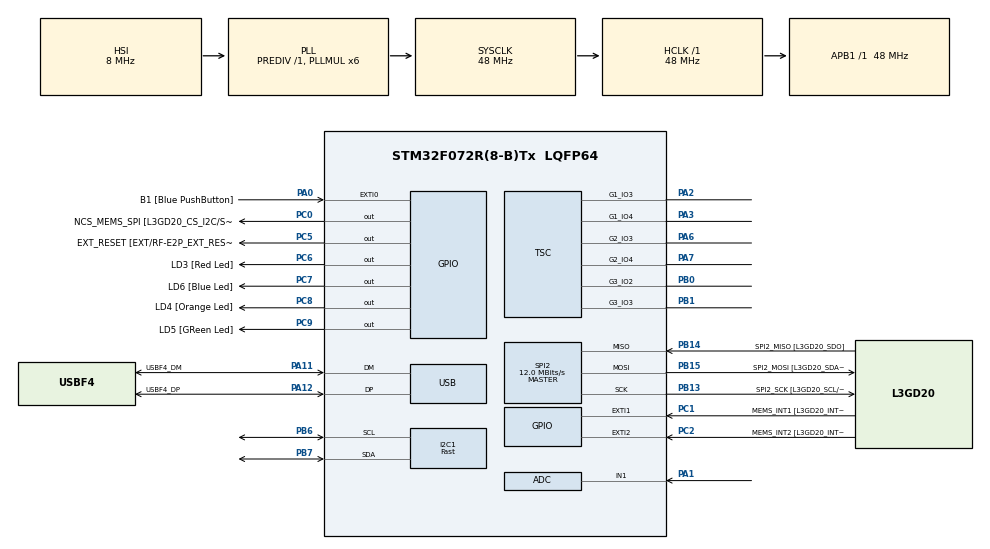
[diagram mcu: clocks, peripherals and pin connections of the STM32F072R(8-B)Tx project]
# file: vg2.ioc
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I2C1.I2C_Speed_Mode=I2C_Fast
I2C1.Timing=0x0010020A
Mcu.Family=STM32F0
Mcu.Name=STM32F072R(8-B)Tx
Mcu.Package=LQFP64
Mcu.UserConstants=dingastest,2137
PA0.GPIO_Label=B1 [Blue PushButton]
PA0.GPIO_ModeDefaultEXTI=GPIO_MODE_EVT_RISING
PA0.Signal=GPXTI0
PA1.Mode=IN1
PA1.Signal=ADC_IN1
PA11.GPIO_Label=USBF4_DM
PA11.Mode=Device
PA11.Signal=USB_DM
PA12.GPIO_Label=USBF4_DP
PA12.Mode=Device
PA12.Signal=USB_DP
PA13.GPIO_Label=SWDIO
PA13.Mode=Serial_Wire
PA13.Signal=SYS_SWDIO
PA14.GPIO_Label=SWCLK
PA14.Mode=Serial_Wire
PA14.Signal=SYS_SWCLK
PA2.Mode=G1_IO3-Channel
PA2.Signal=TSC_G1_IO3
PA3.Mode=G1_IO4-Sampling
PA3.Signal=TSC_G1_IO4
PA6.Mode=G2_IO3-Channel
PA6.Signal=TSC_G2_IO3
PA7.Mode=G2_IO4-Sampling
PA7.Signal=TSC_G2_IO4
PB0.Mode=G3_IO2-Channel
PB0.Signal=TSC_G3_IO2
PB1.Mode=G3_IO3-Sampling
PB1.Signal=TSC_G3_IO3
PB10.GPIO_Label=I2C2_SCL[EXT/RF-E2P_SCL]
PB10.GPIO_Pu=GPIO_PULLUP
PB10.Signal=I2C2_SCL
PB11.GPIO_Label=I2C2_SDA[EXT/RF-E2P_SDA]
PB11.GPIO_Pu=GPIO_PULLUP
PB11.Signal=I2C2_SDA
PB13.GPIO_Label=SPI2_SCK [L3GD20_SCL/SPC]
PB13.Mode=Full_Duplex_Master
PB13.Signal=SPI2_SCK
PB14.GPIO_Label=SPI2_MISO [L3GD20_SDO]
PB14.Mode=Full_Duplex_Master
PB14.Signal=SPI2_MISO
PB15.GPIO_Label=SPI2_MOSI [L3GD20_SDA/SDI]
PB15.Mode=Full_Duplex_Master
PB15.Signal=SPI2_MOSI
PB6.Mode=I2C
PB6.Signal=I2C1_SCL
PB7.Mode=I2C
PB7.Signal=I2C1_SDA
PC0.GPIO_Label=NCS_MEMS_SPI [L3GD20_CS_I2C/SPI]
PC0.Signal=GPIO_Output
PC1.GPIO_Label=MEMS_INT1 [L3GD20_INT1]
PC1.GPIO_ModeDefaultEXTI=GPIO_MODE_EVT_RISING
PC1.Signal=GPXTI1
PC2.GPIO_Label=MEMS_INT2 [L3GD20_INT2]
PC2.GPIO_ModeDefaultEXTI=GPIO_MODE_EVT_RISING
PC2.Signal=GPXTI2
PC5.GPIO_Label=EXT_RESET [EXT/RF-E2P_EXT_RESET]
PC5.Signal=GPIO_Output
PC6.GPIO_Label=LD3 [Red Led]
PC6.Signal=GPIO_Output
PC7.GPIO_Label=LD6 [Blue Led]
PC7.Signal=GPIO_Output
PC8.GPIO_Label=LD4 [Orange Led]
PC8.Signal=GPIO_Output
PC9.GPIO_Label=LD5 [GReen Led]
PC9.Signal=GPIO_Output
ProjectManager.HeapSize=0x200
ProjectManager.StackSize=0x400
ProjectManager.TargetToolchain=STM32CubeIDE
RCC.AHBFreq_Value=48000000
RCC.APB1Freq_Value=48000000
RCC.APB1TimFreq_Value=48000000
RCC.HCLKFreq_Value=48000000
RCC.PLLMUL=RCC_PLL_MUL6
RCC.SYSCLKFreq_VALUE=48000000
RCC.SYSCLKSource=RCC_SYSCLKSOURCE_PLLCLK
SPI2.BaudRatePrescaler=SPI_BAUDRATEPRESCALER_4
SPI2.CalculateBaudRate=12.0 MBits/s
SPI2.Direction=SPI_DIRECTION_2LINES
SPI2.Mode=SPI_MODE_MASTER
SPI2.VirtualType=VM_MASTER
TSC.ChannelIOs-G1_IO3=TSC_GROUP1_IO3
TSC.ChannelIOs-G2_IO3=TSC_GROUP2_IO3
TSC.ChannelIOs-G3_IO2=TSC_GROUP3_IO2
TSC.SamplingIOs-G1_IO4=TSC_GROUP1_IO4
TSC.SamplingIOs-G2_IO4=TSC_GROUP2_IO4
TSC.SamplingIOs-G3_IO3=TSC_GROUP3_IO3
USB.phy_itface=PCD_PHY_EMBEDDED
USB.speed=PCD_SPEED_FULL
board=STM32F072B-DISCO

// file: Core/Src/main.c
/* USER CODE BEGIN Header */
/**
  ******************************************************************************
  * @file           : main.c
  * @brief          : Main program body
  ******************************************************************************
  * @attention
  *
  * Copyright (c) 2025 STMicroelectronics.
  * All rights reserved.
  *
  * This software is licensed under terms that can be found in the LICENSE file
  * in the root directory of this software component.
  * If no LICENSE file comes with this software, it is provided AS-IS.
  *
  ******************************************************************************
  */

/* USER CODE END Header */
#include "main.h"

/* USER CODE BEGIN Includes */
#include "ssd1306.h"
#include "ssd1306_tests.h"
#include "ssd1306_fonts.h"
#include <stdio.h>
/* USER CODE END Includes */

ADC_HandleTypeDef hadc;
DMA_HandleTypeDef hdma_adc;

I2C_HandleTypeDef hi2c1;

SPI_HandleTypeDef hspi2;

TSC_HandleTypeDef htsc;

PCD_HandleTypeDef hpcd_USB_FS;

void SystemClock_Config(void);
static void MX_GPIO_Init(void);
static void MX_DMA_Init(void);
static void MX_SPI2_Init(void);
static void MX_TSC_Init(void);
static void MX_USB_PCD_Init(void);
static void MX_I2C1_Init(void);
static void MX_ADC_Init(void);

/* USER CODE BEGIN 0 */

// CONSTS FOR FACES
const unsigned char image_data_demo_angry[] = {
    0x00, 0x00, 0x00, 0x00, 0x00, 0x00, 0x00, 0x00, 0x00, 0x00, 0x00, 0x00, 0x00, 0x00, 0x00, 0x00,
    0x00, 0x00, 0x00, 0x00, 0x00, 0x00, 0x00, 0x00, 0x00, 0x00, 0x00, 0x00, 0x00, 0x00, 0x00, 0x00,
    0x00, 0x00, 0x00, 0x00, 0x00, 0x00, 0x00, 0x00, 0x00, 0x00, 0x00, 0x00, 0x00, 0x00, 0x00, 0x00,
    0x00, 0x00, 0x00, 0x00, 0x00, 0x00, 0x00, 0x00, 0x00, 0x00, 0x00, 0x00, 0x00, 0x00, 0x00, 0x00,
    0x00, 0x00, 0x00, 0x00, 0x00, 0x00, 0x00, 0x00, 0x00, 0x00, 0x00, 0x00, 0x00, 0x00, 0x00, 0x00,
    0x00, 0x00, 0x00, 0x00, 0x00, 0x00, 0x00, 0x00, 0x00, 0x00, 0x00, 0x00, 0x00, 0x00, 0x00, 0x00,
    0x00, 0x00, 0x00, 0x00, 0x00, 0x00, 0x00, 0x00, 0x00, 0x00, 0x00, 0x00, 0x00, 0x00, 0x00, 0x00,
    0x00, 0x00, 0x00, 0x00, 0x00, 0x00, 0x00, 0x00, 0x00, 0x00, 0x00, 0x00, 0x00, 0x00, 0x00, 0x00,
    0x00, 0x00, 0x00, 0x00, 0x00, 0x00, 0x00, 0x00, 0x00, 0x00, 0x00, 0x00, 0x00, 0x00, 0x00, 0x00,
    0x00, 0x00, 0x00, 0x00, 0x00, 0x00, 0x80, 0x00, 0x00, 0x04, 0x00, 0x00, 0x00, 0x00, 0x00, 0x00,
    0x00, 0x00, 0x00, 0x00, 0x00, 0x01, 0xE0, 0x00, 0x00, 0x0E, 0x00, 0x00, 0x00, 0x00, 0x00, 0x00,
    0x00, 0x00, 0x00, 0x00, 0x00, 0x01, 0xF8, 0x00, 0x00, 0x1E, 0x00, 0x00, 0x00, 0x00, 0x00, 0x00,
    0x00, 0x00, 0x00, 0x00, 0x00, 0x00, 0xFE, 0x00, 0x00, 0x3C, 0x00, 0x00, 0x00, 0x00, 0x00, 0x00,
    0x00, 0x00, 0x00, 0x00, 0x00, 0x00, 0x3F, 0x00, 0x00, 0x78, 0x00, 0x00, 0x00, 0x00, 0x00, 0x00,
    0x00, 0x00, 0x00, 0x00, 0x00, 0x00, 0x1F, 0xC0, 0x00, 0xF0, 0x00, 0x00, 0x00, 0x00, 0x00, 0x00,
    0x00, 0x00, 0x00, 0x00, 0x00, 0x00, 0x07, 0xE0, 0x03, 0xE0, 0x00, 0x00, 0x00, 0x00, 0x00, 0x00,
    0x00, 0x00, 0x00, 0x00, 0x00, 0x00, 0x01, 0xF8, 0x07, 0xC0, 0x00, 0x00, 0x00, 0x00, 0x00, 0x00,
    0x00, 0x00, 0x00, 0x00, 0x00, 0x00, 0x00, 0x7C, 0x0F, 0x00, 0x00, 0x00, 0x00, 0x00, 0x00, 0x00,
    0x00, 0x00, 0x00, 0x00, 0x00, 0x00, 0x00, 0x3E, 0x1E, 0x00, 0x00, 0x00, 0x00, 0x00, 0x00, 0x00,
    0x00, 0x00, 0x00, 0x00, 0x00, 0x01, 0xE0, 0x0F, 0x3C, 0x03, 0xC0, 0x00, 0x00, 0x00, 0x00, 0x00,
    0x00, 0x00, 0x00, 0x00, 0x00, 0x03, 0xF0, 0x06, 0x18, 0x07, 0xE0, 0x00, 0x00, 0x00, 0x00, 0x00,
    0x00, 0x00, 0x00, 0x00, 0x00, 0x07, 0xF8, 0x00, 0x00, 0x0F, 0xF0, 0x00, 0x00, 0x00, 0x00, 0x00,
    0x00, 0x00, 0x00, 0x00, 0x00, 0x0F, 0xFC, 0x00, 0x00, 0x1F, 0xF8, 0x00, 0x00, 0x00, 0x00, 0x00,
    0x00, 0x00, 0x00, 0x00, 0x00, 0x0F, 0xFC, 0x00, 0x00, 0x1F, 0xF8, 0x00, 0x00, 0x00, 0x00, 0x00,
    0x00, 0x00, 0x00, 0x00, 0x00, 0x0F, 0xFC, 0x00, 0x00, 0x1F, 0xF8, 0x00, 0x00, 0x00, 0x00, 0x00,
    0x00, 0x00, 0x00, 0x00, 0x00, 0x0F, 0xFC, 0x00, 0x00, 0x1F, 0xF8, 0x00, 0x00, 0x00, 0x00, 0x00,
    0x00, 0x00, 0x00, 0x00, 0x00, 0x07, 0xF8, 0x00, 0x00, 0x0F, 0xF0, 0x00, 0x00, 0x00, 0x00, 0x00,
    0x00, 0x00, 0x00, 0x00, 0x00, 0x03, 0xF0, 0x00, 0x00, 0x07, 0xE0, 0x00, 0x00, 0x00, 0x00, 0x00,
    0x00, 0x00, 0x00, 0x00, 0x00, 0x01, 0xE0, 0x00, 0x00, 0x03, 0xC0, 0x00, 0x00, 0x00, 0x00, 0x00,
    0x00, 0x00, 0x00, 0x00, 0x00, 0x00, 0x00, 0x00, 0x00, 0x00, 0x00, 0x00, 0x00, 0x00, 0x00, 0x00,
    0x00, 0x00, 0x00, 0x00, 0x00, 0x00, 0x00, 0x00, 0x00, 0x00, 0x00, 0x00, 0x00, 0x00, 0x00, 0x00,
    0x00, 0x00, 0x00, 0x00, 0x00, 0x00, 0x00, 0x00, 0x00, 0x00, 0x00, 0x00, 0x00, 0x00, 0x00, 0x00,
    0x00, 0x00, 0x00, 0x00, 0x00, 0x00, 0x00, 0x03, 0x80, 0x00, 0x00, 0x00, 0x00, 0x00, 0x00, 0x00,
    0x00, 0x00, 0x00, 0x00, 0x00, 0x00, 0x00, 0x07, 0xC0, 0x00, 0x00, 0x00, 0x00, 0x00, 0x00, 0x00,
    0x00, 0x00, 0x00, 0x00, 0x00, 0x00, 0x00, 0x07, 0xE0, 0x00, 0x00, 0x00, 0x00, 0x00, 0x00, 0x00,
    0x00, 0x00, 0x00, 0x00, 0x00, 0x00, 0x00, 0x0E, 0xF0, 0x00, 0x00, 0x00, 0x00, 0x00, 0x00, 0x00,
    0x00, 0x00, 0x00, 0x00, 0x00, 0x00, 0x00, 0x1E, 0x78, 0x00, 0x00, 0x00, 0x00, 0x00, 0x00, 0x00,
    0x00, 0x00, 0x00, 0x00, 0x00, 0x00, 0x00, 0x3C, 0x3C, 0x00, 0x00, 0x00, 0x00, 0x00, 0x00, 0x00,
    0x00, 0x00, 0x00, 0x00, 0x00, 0x00, 0x00, 0x78, 0x1E, 0x00, 0x00, 0x00, 0x00, 0x00, 0x00, 0x00,
    0x00, 0x00, 0x00, 0x00, 0x00, 0x00, 0x00, 0x70, 0x0F, 0x00, 0x00, 0x00, 0x00, 0x00, 0x00, 0x00,
    0x00, 0x00, 0x00, 0x00, 0x00, 0x00, 0x00, 0xF0, 0x03, 0x80, 0x00, 0x00, 0x00, 0x00, 0x00, 0x00,
    0x00, 0x00, 0x00, 0x00, 0x00, 0x00, 0x00, 0xE0, 0x03, 0xC0, 0x00, 0x00, 0x00, 0x00, 0x00, 0x00,
    0x00, 0x00, 0x00, 0x00, 0x00, 0x00, 0x00, 0x40, 0x01, 0x80, 0x00, 0x00, 0x00, 0x00, 0x00, 0x00,
    0x00, 0x00, 0x00, 0x00, 0x00, 0x00, 0x00, 0x00, 0x00, 0x00, 0x00, 0x00, 0x00, 0x00, 0x00, 0x00,
    0x00, 0x00, 0x00, 0x00, 0x00, 0x00, 0x00, 0x00, 0x00, 0x00, 0x00, 0x00, 0x00, 0x00, 0x00, 0x00,
    0x00, 0x00, 0x00, 0x00, 0x00, 0x00, 0x00, 0x00, 0x00, 0x00, 0x00, 0x00, 0x00, 0x00, 0x00, 0x00,
    0x00, 0x00, 0x00, 0x00, 0x00, 0x00, 0x00, 0x00, 0x00, 0x00, 0x00, 0x00, 0x00, 0x00, 0x00, 0x00,
    0x00, 0x00, 0x00, 0x00, 0x00, 0x00, 0x00, 0x00, 0x00, 0x00, 0x00, 0x00, 0x00, 0x00, 0x00, 0x00,
    0x00, 0x00, 0x00, 0x00, 0x00, 0x00, 0x00, 0x00, 0x00, 0x00, 0x00, 0x00, 0x00, 0x00, 0x00, 0x00,
    0x00, 0x00, 0x00, 0x00, 0x00, 0x00, 0x00, 0x00, 0x00, 0x00, 0x00, 0x00, 0x00, 0x00, 0x00, 0x00,
    0x00, 0x00, 0x00, 0x00, 0x00, 0x00, 0x00, 0x00, 0x00, 0x00, 0x00, 0x00, 0x00, 0x00, 0x00, 0x00,
    0x00, 0x00, 0x00, 0x00, 0x00, 0x00, 0x00, 0x00, 0x00, 0x00, 0x00, 0x00, 0x00, 0x00, 0x00, 0x00,
    0x00, 0x00, 0x00, 0x00, 0x00, 0x00, 0x00, 0x00, 0x00, 0x00, 0x00, 0x00, 0x00, 0x00, 0x00, 0x00,
    0x00, 0x00, 0x00, 0x00, 0x00, 0x00, 0x00, 0x00, 0x00, 0x00, 0x00, 0x00, 0x00, 0x00, 0x00, 0x00,
    0x00, 0x00, 0x00, 0x00, 0x00, 0x00, 0x00, 0x00, 0x00, 0x00, 0x00, 0x00, 0x00, 0x00, 0x00, 0x00,
    0x00, 0x00, 0x00, 0x00, 0x00, 0x00, 0x00, 0x00, 0x00, 0x00, 0x00, 0x00, 0x00, 0x00, 0x00, 0x00,
    0x00, 0x00, 0x00, 0x00, 0x00, 0x00, 0x00, 0x00, 0x00, 0x00, 0x00, 0x00, 0x00, 0x00, 0x00, 0x00,
    0x00, 0x00, 0x00, 0x00, 0x00, 0x00, 0x00, 0x00, 0x00, 0x00, 0x00, 0x00, 0x00, 0x00, 0x00, 0x00,
    0x00, 0x00, 0x00, 0x00, 0x00, 0x00, 0x00, 0x00, 0x00, 0x00, 0x00, 0x00, 0x00, 0x00, 0x00, 0x00,
    0x00, 0x00, 0x00, 0x00, 0x00, 0x00, 0x00, 0x00, 0x00, 0x00, 0x00, 0x00, 0x00, 0x00, 0x00, 0x00,
    0x00, 0x00, 0x00, 0x00, 0x00, 0x00, 0x00, 0x00, 0x00, 0x00, 0x00, 0x00, 0x00, 0x00, 0x00, 0x00,
    0x00, 0x00, 0x00, 0x00, 0x00, 0x00, 0x00, 0x00, 0x00, 0x00, 0x00, 0x00, 0x00, 0x00, 0x00, 0x00,
    0x00, 0x00, 0x00, 0x00, 0x00, 0x00, 0x00, 0x00, 0x00, 0x00, 0x00, 0x00, 0x00, 0x00, 0x00, 0x00,
    0x00, 0x00, 0x00, 0x00, 0x00, 0x00, 0x00, 0x00, 0x00, 0x00, 0x00, 0x00, 0x00, 0x00, 0x00, 0x00
};

const unsigned char image_data_demo_smiley[] = {
    0x00, 0x00, 0x00, 0x00, 0x00, 0x00, 0x00, 0x00, 0x00, 0x00, 0x00, 0x00, 0x00, 0x00, 0x00, 0x00,
    0x00, 0x00, 0x00, 0x00, 0x00, 0x00, 0x00, 0x00, 0x00, 0x00, 0x00, 0x00, 0x00, 0x00, 0x00, 0x00,
    0x00, 0x00, 0x00, 0x00, 0x00, 0x00, 0x00, 0x00, 0x00, 0x00, 0x00, 0x00, 0x00, 0x00, 0x00, 0x00,
    0x00, 0x00, 0x00, 0x00, 0x00, 0x00, 0x00, 0x00, 0x00, 0x00, 0x00, 0x00, 0x00, 0x00, 0x00, 0x00,
    0x00, 0x00, 0x00, 0x00, 0x00, 0x00, 0x00, 0x00, 0x00, 0x00, 0x00, 0x00, 0x00, 0x00, 0x00, 0x00,
    0x00, 0x00, 0x00, 0x00, 0x00, 0x00, 0x00, 0x00, 0x00, 0x00, 0x00, 0x00, 0x00, 0x00, 0x00, 0x00,
    0x00, 0x00, 0x00, 0x00, 0x00, 0x00, 0x00, 0x00, 0x00, 0x00, 0x00, 0x00, 0x00, 0x00, 0x00, 0x00,
    0x00, 0x00, 0x00, 0x00, 0x00, 0x00, 0x00, 0x00, 0x00, 0x00, 0x00, 0x00, 0x00, 0x00, 0x00, 0x00,
    0x00, 0x00, 0x00, 0x00, 0x00, 0x00, 0x00, 0x00, 0x00, 0x00, 0x00, 0x00, 0x00, 0x00, 0x00, 0x00,
    0x00, 0x00, 0x00, 0x00, 0x00, 0x00, 0x00, 0x00, 0x00, 0x00, 0x00, 0x00, 0x00, 0x00, 0x00, 0x00,
    0x00, 0x00, 0x00, 0x00, 0x00, 0x00, 0x00, 0x00, 0x00, 0x00, 0x00, 0x00, 0x00, 0x00, 0x00, 0x00,
    0x00, 0x00, 0x00, 0x00, 0x00, 0x00, 0x00, 0x00, 0x00, 0x00, 0x00, 0x00, 0x00, 0x00, 0x00, 0x00,
    0x00, 0x00, 0x00, 0x00, 0x00, 0x00, 0x00, 0x00, 0x00, 0x00, 0x00, 0x00, 0x00, 0x00, 0x00, 0x00,
    0x00, 0x00, 0x00, 0x00, 0x00, 0x00, 0x00, 0x00, 0x00, 0x00, 0x00, 0x00, 0x00, 0x00, 0x00, 0x00,
    0x00, 0x00, 0x00, 0x00, 0x00, 0x00, 0x00, 0x00, 0x00, 0x00, 0x00, 0x00, 0x00, 0x00, 0x00, 0x00,
    0x00, 0x00, 0x00, 0x00, 0x00, 0x00, 0x00, 0x00, 0x00, 0x00, 0x00, 0x00, 0x00, 0x00, 0x00, 0x00,
    0x00, 0x00, 0x00, 0x00, 0x00, 0x00, 0x00, 0x00, 0x00, 0x00, 0x00, 0x00, 0x00, 0x00, 0x00, 0x00,
    0x00, 0x00, 0x00, 0x00, 0x00, 0x00, 0x00, 0x00, 0x00, 0x00, 0x00, 0x00, 0x00, 0x00, 0x00, 0x00,
    0x00, 0x00, 0x00, 0x00, 0x00, 0x00, 0x00, 0x00, 0x00, 0x00, 0x00, 0x00, 0x00, 0x00, 0x00, 0x00,
    0x00, 0x00, 0x00, 0x00, 0x00, 0x01, 0xE0, 0x00, 0x00, 0x03, 0xC0, 0x00, 0x00, 0x00, 0x00, 0x00,
    0x00, 0x00, 0x00, 0x00, 0x00, 0x03, 0xF0, 0x00, 0x00, 0x07, 0xE0, 0x00, 0x00, 0x00, 0x00, 0x00,
    0x00, 0x00, 0x00, 0x00, 0x00, 0x07, 0xF8, 0x00, 0x00, 0x0F, 0xF0, 0x00, 0x00, 0x00, 0x00, 0x00,
    0x00, 0x00, 0x00, 0x00, 0x00, 0x0F, 0xFC, 0x00, 0x00, 0x1F, 0xF8, 0x00, 0x00, 0x00, 0x00, 0x00,
    0x00, 0x00, 0x00, 0x00, 0x00, 0x0F, 0xFC, 0x00, 0x00, 0x1F, 0xF8, 0x00, 0x00, 0x00, 0x00, 0x00,
    0x00, 0x00, 0x00, 0x00, 0x00, 0x0F, 0xFC, 0x00, 0x00, 0x1F, 0xF8, 0x00, 0x00, 0x00, 0x00, 0x00,
    0x00, 0x00, 0x00, 0x00, 0x00, 0x0F, 0xFC, 0x00, 0x00, 0x1F, 0xF8, 0x00, 0x00, 0x00, 0x00, 0x00,
    0x00, 0x00, 0x00, 0x00, 0x00, 0x07, 0xF8, 0x00, 0x00, 0x0F, 0xF0, 0x00, 0x00, 0x00, 0x00, 0x00,
    0x00, 0x00, 0x00, 0x00, 0x00, 0x03, 0xF0, 0x00, 0x00, 0x07, 0xE0, 0x00, 0x00, 0x00, 0x00, 0x00,
    0x00, 0x00, 0x00, 0x00, 0x00, 0x01, 0xE0, 0x00, 0x00, 0x03, 0xC0, 0x00, 0x00, 0x00, 0x00, 0x00,
    0x00, 0x00, 0x00, 0x00, 0x00, 0x00, 0x00, 0x00, 0x00, 0x00, 0x00, 0x00, 0x00, 0x00, 0x00, 0x00,
    0x00, 0x00, 0x00, 0x00, 0x00, 0x00, 0x00, 0x00, 0x00, 0x00, 0x00, 0x00, 0x00, 0x00, 0x00, 0x00,
    0x00, 0x00, 0x00, 0x00, 0x00, 0x00, 0x00, 0x00, 0x00, 0x00, 0x00, 0x00, 0x00, 0x00, 0x00, 0x00,
    0x00, 0x00, 0x00, 0x00, 0x00, 0x00, 0x00, 0x00, 0x00, 0x00, 0x00, 0x00, 0x00, 0x00, 0x00, 0x00,
    0x00, 0x00, 0x00, 0x00, 0x00, 0x00, 0x00, 0x00, 0x00, 0x00, 0x00, 0x00, 0x00, 0x00, 0x00, 0x00,
    0x00, 0x00, 0x00, 0x00, 0x00, 0x00, 0x00, 0x00, 0x00, 0x00, 0x00, 0x00, 0x00, 0x00, 0x00, 0x00,
    0x00, 0x00, 0x00, 0x00, 0x00, 0x00, 0x00, 0x01, 0x00, 0x00, 0x00, 0x00, 0x00, 0x00, 0x00, 0x00,
    0x00, 0x00, 0x00, 0x00, 0x00, 0x00, 0x04, 0x03, 0x80, 0x60, 0x00, 0x00, 0x00, 0x00, 0x00, 0x00,
    0x00, 0x00, 0x00, 0x00, 0x00, 0x00, 0x0E, 0x03, 0xC0, 0xF0, 0x00, 0x00, 0x00, 0x00, 0x00, 0x00,
    0x00, 0x00, 0x00, 0x00, 0x00, 0x00, 0x0F, 0x87, 0xE1, 0xE0, 0x00, 0x00, 0x00, 0x00, 0x00, 0x00,
    0x00, 0x00, 0x00, 0x00, 0x00, 0x00, 0x07, 0xFF, 0xFF, 0xC0, 0x00, 0x00, 0x00, 0x00, 0x00, 0x00,
    0x00, 0x00, 0x00, 0x00, 0x00, 0x00, 0x03, 0xFE, 0x7F, 0x80, 0x00, 0x00, 0x00, 0x00, 0x00, 0x00,
    0x00, 0x00, 0x00, 0x00, 0x00, 0x00, 0x00, 0xFC, 0x3F, 0x00, 0x00, 0x00, 0x00, 0x00, 0x00, 0x00,
    0x00, 0x00, 0x00, 0x00, 0x00, 0x00, 0x00, 0x00, 0x00, 0x00, 0x00, 0x00, 0x00, 0x00, 0x00, 0x00,
    0x00, 0x00, 0x00, 0x00, 0x00, 0x00, 0x00, 0x00, 0x00, 0x00, 0x00, 0x00, 0x00, 0x00, 0x00, 0x00,
    0x00, 0x00, 0x00, 0x00, 0x00, 0x00, 0x00, 0x00, 0x00, 0x00, 0x00, 0x00, 0x00, 0x00, 0x00, 0x00,
    0x00, 0x00, 0x00, 0x00, 0x00, 0x00, 0x00, 0x00, 0x00, 0x00, 0x00, 0x00, 0x00, 0x00, 0x00, 0x00,
    0x00, 0x00, 0x00, 0x00, 0x00, 0x00, 0x00, 0x00, 0x00, 0x00, 0x00, 0x00, 0x00, 0x00, 0x00, 0x00,
    0x00, 0x00, 0x00, 0x00, 0x00, 0x00, 0x00, 0x00, 0x00, 0x00, 0x00, 0x00, 0x00, 0x00, 0x00, 0x00,
    0x00, 0x00, 0x00, 0x00, 0x00, 0x00, 0x00, 0x00, 0x00, 0x00, 0x00, 0x00, 0x00, 0x00, 0x00, 0x00,
    0x00, 0x00, 0x00, 0x00, 0x00, 0x00, 0x00, 0x00, 0x00, 0x00, 0x00, 0x00, 0x00, 0x00, 0x00, 0x00,
    0x00, 0x00, 0x00, 0x00, 0x00, 0x00, 0x00, 0x00, 0x00, 0x00, 0x00, 0x00, 0x00, 0x00, 0x00, 0x00,
    0x00, 0x00, 0x00, 0x00, 0x00, 0x00, 0x00, 0x00, 0x00, 0x00, 0x00, 0x00, 0x00, 0x00, 0x00, 0x00,
    0x00, 0x00, 0x00, 0x00, 0x00, 0x00, 0x00, 0x00, 0x00, 0x00, 0x00, 0x00, 0x00, 0x00, 0x00, 0x00,
    0x00, 0x00, 0x00, 0x00, 0x00, 0x00, 0x00, 0x00, 0x00, 0x00, 0x00, 0x00, 0x00, 0x00, 0x00, 0x00,
    0x00, 0x00, 0x00, 0x00, 0x00, 0x00, 0x00, 0x00, 0x00, 0x00, 0x00, 0x00, 0x00, 0x00, 0x00, 0x00,
    0x00, 0x00, 0x00, 0x00, 0x00, 0x00, 0x00, 0x00, 0x00, 0x00, 0x00, 0x00, 0x00, 0x00, 0x00, 0x00,
    0x00, 0x00, 0x00, 0x00, 0x00, 0x00, 0x00, 0x00, 0x00, 0x00, 0x00, 0x00, 0x00, 0x00, 0x00, 0x00,
    0x00, 0x00, 0x00, 0x00, 0x00, 0x00, 0x00, 0x00, 0x00, 0x00, 0x00, 0x00, 0x00, 0x00, 0x00, 0x00,
    0x00, 0x00, 0x00, 0x00, 0x00, 0x00, 0x00, 0x00, 0x00, 0x00, 0x00, 0x00, 0x00, 0x00, 0x00, 0x00,
    0x00, 0x00, 0x00, 0x00, 0x00, 0x00, 0x00, 0x00, 0x00, 0x00, 0x00, 0x00, 0x00, 0x00, 0x00, 0x00,
    0x00, 0x00, 0x00, 0x00, 0x00, 0x00, 0x00, 0x00, 0x00, 0x00, 0x00, 0x00, 0x00, 0x00, 0x00, 0x00,
    0x00, 0x00, 0x00, 0x00, 0x00, 0x00, 0x00, 0x00, 0x00, 0x00, 0x00, 0x00, 0x00, 0x00, 0x00, 0x00,
    0x00, 0x00, 0x00, 0x00, 0x00, 0x00, 0x00, 0x00, 0x00, 0x00, 0x00, 0x00, 0x00, 0x00, 0x00, 0x00,
    0x00, 0x00, 0x00, 0x00, 0x00, 0x00, 0x00, 0x00, 0x00, 0x00, 0x00, 0x00, 0x00, 0x00, 0x00, 0x00
};

const unsigned char image_data_cry_1[] = {
    0xFF, 0xFF, 0xFF, 0xFF, 0xFF, 0xFF, 0xFF, 0xFF, 0xFF, 0xFF, 0xFF, 0xFF, 0xFF, 0xFF, 0xFF, 0xFF,
    0xFF, 0xFF, 0xFF, 0xFF, 0xFF, 0xFF, 0xFF, 0xFF, 0xFF, 0xFF, 0xFF, 0xFF, 0xFF, 0xFF, 0xFF, 0xFF,
    0xFF, 0xFF, 0xFF, 0xFF, 0xFF, 0xFF, 0xFF, 0xFF, 0xFF, 0xFF, 0xFF, 0xFF, 0xFF, 0xFF, 0xFF, 0xFF,
    0xFF, 0xFF, 0xFF, 0xFF, 0xFF, 0xFF, 0xFF, 0xFF, 0xFF, 0xFF, 0xFF, 0xFF, 0xFF, 0xFF, 0xFF, 0xFF,
    0xFF, 0xFF, 0xFF, 0xFF, 0xFF, 0xFF, 0xFF, 0xFF, 0xFF, 0xFF, 0xFF, 0xFF, 0xFF, 0xFF, 0xFF, 0xFF,
    0xFF, 0xFF, 0xFF, 0xFF, 0xFF, 0xFF, 0xFF, 0xFF, 0xFF, 0xFF, 0xFF, 0xFF, 0xFF, 0xFF, 0xFF, 0xFF,
    0xFF, 0xFF, 0xFF, 0xFF, 0xFF, 0xFF, 0xFF, 0xFF, 0xFF, 0xFF, 0xFF, 0xFF, 0xFF, 0xFF, 0xFF, 0xFF,
    0xFF, 0xFF, 0xFF, 0xFF, 0xFF, 0xFF, 0xFF, 0xFF, 0xFF, 0xFF, 0xFF, 0xFF, 0xFF, 0xFF, 0xFF, 0xFF,
    0xFF, 0xFF, 0xFF, 0xFF, 0xFF, 0xE7, 0xFF, 0xFF, 0xFF, 0xDF, 0xFF, 0xFF, 0xFF, 0xFF, 0xFF, 0xFF,
    0xFF, 0xFF, 0xFF, 0xFF, 0xFF, 0xCB, 0xFF, 0xFF, 0xFF, 0x87, 0xFF, 0xFF, 0xFF, 0xFF, 0xFF, 0xFF,
    0xFF, 0xFF, 0xFF, 0xFF, 0xFF, 0x9D, 0xFF, 0xFF, 0xFF, 0x33, 0xFF, 0xFF, 0xFF, 0xFF, 0xFF, 0xFF,
    0xFF, 0xFF, 0xFF, 0xFF, 0xFF, 0x3E, 0xFF, 0xFF, 0xFC, 0x79, 0xFF, 0xFF, 0xFF, 0xFF, 0xFF, 0xFF,
    0xFF, 0xFF, 0xFF, 0xFF, 0xFF, 0x7F, 0x7F, 0xFF, 0xF9, 0xFE, 0xFF, 0xFF, 0xFF, 0xFF, 0xFF, 0xFF,
    0xFF, 0xFF, 0xFF, 0xFF, 0xFE, 0xFF, 0x3F, 0xFF, 0xF3, 0xFF, 0x7F, 0xFF, 0xFF, 0xFF, 0xFF, 0xFF,
    0xFF, 0xFF, 0xFF, 0xFF, 0xFD, 0xFF, 0x9F, 0xFF, 0xF7, 0xFF, 0xBF, 0xFF, 0xFF, 0xFF, 0xFF, 0xFF,
    0xFF, 0xFF, 0xFF, 0xFF, 0xF9, 0xFF, 0xCF, 0xFF, 0xE7, 0xFF, 0xDF, 0xFF, 0xFF, 0xFF, 0xFF, 0xFF,
    0xFF, 0xFF, 0xFF, 0xFF, 0xF3, 0xFF, 0xEF, 0xFF, 0xEF, 0xFF, 0xDF, 0xFF, 0xFF, 0xFF, 0xFF, 0xFF,
    0xFF, 0xFF, 0xFF, 0xFF, 0xF7, 0xFF, 0xF7, 0xFF, 0xDF, 0xFF, 0xEF, 0xFF, 0xFF, 0xFF, 0xFF, 0xFF,
    0xFF, 0xFF, 0xFF, 0xFF, 0xF7, 0xFF, 0xF3, 0xFF, 0xDF, 0xFF, 0xF7, 0xFF, 0xFF, 0xFF, 0xFF, 0xFF,
    0xFF, 0xFF, 0xFF, 0xFF, 0xE7, 0xFF, 0xF8, 0x3F, 0xDF, 0xFF, 0xFB, 0xFF, 0xFF, 0xFF, 0xFF, 0xFF,
    0xFF, 0xFF, 0xFF, 0xFF, 0xEF, 0xFF, 0xFF, 0x80, 0x3F, 0xFF, 0xFB, 0xFF, 0xFF, 0xFF, 0xFF, 0xFF,
    0xFF, 0xFF, 0xFF, 0xFF, 0xEF, 0xF3, 0xFF, 0xFF, 0xE7, 0xFF, 0xFD, 0xFF, 0xFF, 0xFF, 0xFF, 0xFF,
    0xFF, 0xFF, 0xFF, 0xFF, 0xEF, 0xF8, 0xFF, 0xFF, 0xE1, 0x61, 0x3E, 0xFF, 0xFF, 0xFF, 0xFF, 0xFF,
    0xFF, 0xFF, 0xFF, 0xFF, 0xEF, 0xC0, 0x07, 0xE0, 0xF0, 0x0B, 0xBE, 0xFF, 0xFF, 0xFF, 0xFF, 0xFF,
    0xFF, 0xFF, 0xFF, 0xFF, 0xEE, 0x99, 0xF7, 0xEC, 0xF3, 0xF9, 0xA6, 0xFF, 0xFF, 0xFF, 0xFF, 0xFF,
    0xFF, 0xFF, 0xFF, 0xFF, 0xEE, 0x5B, 0x7F, 0xE1, 0xFF, 0xDD, 0x57, 0x7F, 0xFF, 0xFF, 0xFF, 0xFF,
    0xFF, 0xFF, 0xFF, 0xFF, 0xEF, 0x3F, 0xFF, 0xF7, 0xFF, 0xFF, 0xD8, 0x3F, 0xFF, 0xFF, 0xFF, 0xFF,
    0xFF, 0xFF, 0xFF, 0xFF, 0xCD, 0x5F, 0xFF, 0xFF, 0xFF, 0xFF, 0xDF, 0x3F, 0xFF, 0xFF, 0xFF, 0xFF,
    0xFF, 0xFF, 0xFF, 0xFF, 0x9A, 0x80, 0x00, 0x00, 0x00, 0x01, 0xDE, 0xBF, 0xFF, 0xFF, 0xFF, 0xFF,
    0xFF, 0xFF, 0xFF, 0xFF, 0xB4, 0x92, 0x4E, 0xF2, 0xEC, 0x91, 0xEE, 0x1F, 0xFF, 0xFF, 0xFF, 0xFF,
    0xFF, 0xFF, 0xFF, 0xFF, 0x73, 0xB4, 0x9F, 0xFF, 0xFF, 0xA5, 0xEF, 0xAF, 0xFF, 0xFF, 0xFF, 0xFF,
    0xFF, 0xFF, 0xFF, 0xFF, 0x69, 0xBF, 0xFF, 0xFE, 0x0F, 0xFD, 0xF7, 0x2F, 0xFF, 0xFF, 0xFF, 0xFF,
    0xFF, 0xFF, 0xFF, 0xFE, 0x55, 0xBF, 0xFE, 0x00, 0x01, 0xFD, 0xF7, 0xB7, 0xFF, 0xFF, 0xFF, 0xFF,
    0xFF, 0xFF, 0xFF, 0xFE, 0xCB, 0xBF, 0xE0, 0x00, 0x00, 0x7C, 0xFB, 0x9B, 0xFF, 0xFF, 0xFF, 0xFF,
    0xFF, 0xFF, 0xFF, 0xFE, 0xA7, 0xBF, 0x80, 0x00, 0x00, 0x1E, 0xFB, 0xBB, 0xFF, 0xFF, 0xFF, 0xFF,
    0xFF, 0xFF, 0xFF, 0xFE, 0xB3, 0xBC, 0x00, 0x00, 0x01, 0x4E, 0xFB, 0x8B, 0xFF, 0xFF, 0xFF, 0xFF,
    0xFF, 0xFF, 0xFF, 0xFE, 0x97, 0xBE, 0x80, 0x00, 0x01, 0x3E, 0xFD, 0xAD, 0xFF, 0xFF, 0xFF, 0xFF,
    0xFF, 0xFF, 0xFF, 0xFE, 0x67, 0x9F, 0x40, 0x08, 0x89, 0xFE, 0xFD, 0xB5, 0xFF, 0xFF, 0xFF, 0xFF,
    0xFF, 0xFF, 0xFF, 0xFE, 0x73, 0x8F, 0xC1, 0x00, 0x01, 0xF8, 0xFD, 0x36, 0xFF, 0xFF, 0xFF, 0xFF,
    0xFF, 0xFF, 0xFF, 0xFE, 0xEB, 0xC1, 0xE0, 0x00, 0x00, 0x20, 0xFE, 0x7A, 0xFF, 0xFF, 0xFF, 0xFF,
    0xFF, 0xFF, 0xFF, 0xFE, 0x43, 0xC0, 0x00, 0x00, 0x00, 0x00, 0x7E, 0x7B, 0x7F, 0xFF, 0xFF, 0xFF,
    0xFF, 0xFF, 0xFF, 0xFE, 0x6B, 0xC0, 0x00, 0x22, 0x00, 0x00, 0x7F, 0xFD, 0x7F, 0xFF, 0xFF, 0xFF,
    0xFF, 0xFF, 0xFF, 0xFF, 0x4B, 0xE0, 0x05, 0x00, 0x20, 0x00, 0x7C, 0xED, 0x7F, 0xFF, 0xFF, 0xFF,
    0xFF, 0xFF, 0xFF, 0xFE, 0xA5, 0xE0, 0x03, 0x00, 0x02, 0x00, 0x74, 0xFF, 0xBF, 0xFF, 0xFF, 0xFF,
    0xFF, 0xFF, 0xFF, 0xEE, 0x95, 0xE0, 0x22, 0x00, 0x00, 0x00, 0x72, 0xFF, 0xFF, 0xFF, 0xFF, 0xFF,
    0xFF, 0xFF, 0xFF, 0xEE, 0xED, 0xF0, 0x87, 0x00, 0x30, 0x22, 0x73, 0x7F, 0xFF, 0xFF, 0xFF, 0xFF,
    0xFF, 0xFF, 0xFF, 0xED, 0xA4, 0xF0, 0x04, 0x10, 0x98, 0x00, 0x7B, 0x7F, 0xFF, 0xFF, 0xFF, 0xFF,
    0xFF, 0xFF, 0xFF, 0xED, 0xB6, 0xF8, 0x0B, 0x39, 0x78, 0x00, 0x7B, 0x6F, 0xFF, 0xFF, 0xFF, 0xFF,
    0xFF, 0xFF, 0xFF, 0xFD, 0xAE, 0xF8, 0x0E, 0x6C, 0x38, 0x00, 0x3B, 0x7E, 0xFF, 0xFF, 0xFF, 0xFF,
    0xFF, 0xFF, 0xFF, 0xEF, 0xA6, 0x7C, 0x00, 0xE7, 0x88, 0x20, 0x3B, 0xFF, 0xFF, 0xFF, 0xFF, 0xFF,
    0xFF, 0xFF, 0xFF, 0xED, 0xEF, 0x7E, 0x01, 0xC3, 0xE0, 0x02, 0x3B, 0x7F, 0xFF, 0xFF, 0xFF, 0xFF,
    0xFF, 0xFF, 0xFF, 0xF7, 0x9F, 0x7E, 0x21, 0xDC, 0xF8, 0x00, 0x3B, 0xFF, 0xFE, 0xFF, 0xFF, 0xFF,
    0xFF, 0xFF, 0xFF, 0xFF, 0xCF, 0x3F, 0x03, 0x9E, 0x3E, 0x00, 0x33, 0xEF, 0xFF, 0xFF, 0xFF, 0xFF,
    0xFF, 0xFF, 0xFF, 0xFD, 0xFF, 0xBF, 0x87, 0x3F, 0x8F, 0x80, 0x37, 0xFF, 0xFF, 0xFF, 0xFF, 0xFF,
    0xFF, 0xFF, 0xFF, 0xFF, 0xFF, 0xDF, 0xC7, 0x7F, 0xE1, 0xF0, 0x37, 0xFF, 0xFF, 0xFF, 0xFF, 0xFF,
    0xFF, 0xFF, 0xFF, 0xFF, 0xFF, 0xCF, 0xEE, 0xFF, 0xFC, 0x1C, 0x37, 0xFF, 0xFF, 0xFF, 0xFF, 0xFF,
    0xFF, 0xFF, 0xFF, 0xBF, 0xBD, 0xEF, 0xFC, 0xFF, 0xFF, 0xC3, 0xE7, 0xFF, 0xFF, 0xFF, 0xFF, 0xFF,
    0xFF, 0xFF, 0xFF, 0xFF, 0xFF, 0xF7, 0xF9, 0xFF, 0xFF, 0xF8, 0x0F, 0xFF, 0xFF, 0xFF, 0xFF, 0xFF,
    0xFF, 0xFF, 0xFF, 0xFF, 0xFF, 0xF3, 0xF3, 0xFF, 0xFF, 0xFF, 0xFF, 0xFF, 0xFF, 0xFF, 0xFF, 0xFF,
    0xFF, 0xFF, 0xFF, 0xFF, 0xFF, 0xF8, 0xE7, 0xFF, 0xFF, 0xFF, 0xFF, 0xFF, 0xFF, 0xFF, 0xFF, 0xFF,
    0xFF, 0xFF, 0xFF, 0xFF, 0xFF, 0xFE, 0x0F, 0xFF, 0xFF, 0xFF, 0xFF, 0xFF, 0xFF, 0xFF, 0xFF, 0xFF,
    0xFF, 0xFF, 0xFF, 0xFF, 0xFF, 0xFF, 0xBF, 0xFF, 0xFF, 0xFF, 0xFF, 0xFF, 0xFF, 0xFF, 0xFF, 0xFF,
    0xFF, 0xFF, 0xFF, 0xFF, 0xFF, 0xFF, 0xFF, 0xFF, 0xFF, 0xFF, 0xFF, 0xFF, 0xFF, 0xFF, 0xFF, 0xFF,
    0xFF, 0xFF, 0xFF, 0xFF, 0xFF, 0xFF, 0xFF, 0xFF, 0xFF, 0xFF, 0xFF, 0xFF, 0xFF, 0xFF, 0xFF, 0xFF
};

const unsigned char image_data_cry_2[] = {
    0xFF, 0xFF, 0xFF, 0xFF, 0xFF, 0xFF, 0xFF, 0xFF, 0xFF, 0xFF, 0xFF, 0xFF, 0xFF, 0xFF, 0xFF, 0xFF,
    0xFF, 0xFF, 0xFF, 0xFF, 0xFF, 0xFF, 0xFF, 0xFF, 0xFF, 0xFF, 0xFF, 0xFF, 0xFF, 0xFF, 0xFF, 0xFF,
    0xFF, 0xFF, 0xFF, 0xFF, 0xFF, 0xFF, 0xFF, 0xFF, 0xFF, 0xFF, 0xFF, 0xFF, 0xFF, 0xFF, 0xFF, 0xFF,
    0xFF, 0xFF, 0xFF, 0xFF, 0xFF, 0xFF, 0xFF, 0xFF, 0xFF, 0xFF, 0xFF, 0xFF, 0xFF, 0xFF, 0xFF, 0xFF,
    0xFF, 0xFF, 0xFF, 0xFF, 0xFF, 0xFF, 0xFF, 0xFF, 0xFF, 0xFF, 0xFF, 0xFF, 0xFF, 0xFF, 0xFF, 0xFF,
    0xFF, 0xFF, 0xFF, 0xFF, 0xFF, 0xFF, 0xFF, 0xFF, 0xFF, 0xFF, 0xFF, 0xFF, 0xFF, 0xFF, 0xFF, 0xFF,
    0xFF, 0xFF, 0xFF, 0xFF, 0xFF, 0xFF, 0xFF, 0xFF, 0xFF, 0xFF, 0xFF, 0xFF, 0xFF, 0xFF, 0xFF, 0xFF,
    0xFF, 0xFF, 0xFF, 0xFF, 0xFF, 0xFF, 0xFF, 0xFF, 0xFF, 0xFF, 0xFF, 0xFF, 0xFF, 0xFF, 0xFF, 0xFF,
    0xFF, 0xFF, 0xFF, 0xFF, 0xFF, 0xE3, 0xFF, 0xFF, 0xFF, 0xEF, 0xFF, 0xFD, 0x7F, 0xFF, 0xFF, 0xFF,
    0xFF, 0xFF, 0xFF, 0xFF, 0xFF, 0xC9, 0xFF, 0xFF, 0xFF, 0x83, 0xFF, 0xFC, 0xFF, 0xFF, 0xFF, 0xFF,
    0xFF, 0xFF, 0xFA, 0xFF, 0xFF, 0x9E, 0x7F, 0xFF, 0xFF, 0x39, 0xFF, 0xFF, 0xFF, 0xFF, 0xFF, 0xFF,
    0xFF, 0xFF, 0xF9, 0xFF, 0xFF, 0x3F, 0x3F, 0xFF, 0xFE, 0x7E, 0x7F, 0xFF, 0xFF, 0xFF, 0xFF, 0xFF,
    0xFF, 0xFF, 0xFF, 0xFF, 0xFF, 0x7F, 0xBF, 0xFF, 0xFC, 0xFF, 0x3F, 0xFF, 0xFF, 0xFF, 0xFF, 0xFF,
    0xFF, 0xFF, 0xFF, 0xFF, 0xFE, 0x7F, 0xDF, 0xFF, 0xF9, 0xFF, 0x9F, 0xFF, 0x89, 0xFF, 0xFF, 0xFF,
    0xFF, 0xFF, 0xFF, 0xFF, 0xFC, 0xFF, 0xEF, 0xFF, 0xF3, 0xFF, 0xCF, 0xFF, 0x7D, 0xFF, 0xFF, 0xFF,
    0xFF, 0xFF, 0xFF, 0xFF, 0xFD, 0xFF, 0xE7, 0xFF, 0xF7, 0xFF, 0xE7, 0xFE, 0xFB, 0xFF, 0xFF, 0xFF,
    0xFF, 0xFF, 0xFF, 0xFF, 0xF9, 0xFF, 0xF3, 0xFF, 0xEF, 0xFF, 0xF7, 0xFD, 0xEF, 0xFF, 0xFF, 0xFF,
    0xFF, 0xFF, 0xFF, 0xFF, 0xF3, 0xFF, 0xFB, 0xFF, 0xCF, 0xFF, 0xF3, 0xFB, 0xDF, 0xFF, 0xFF, 0xFF,
    0xFF, 0xFF, 0xFF, 0xFF, 0xF7, 0xFF, 0xF9, 0xFF, 0xDF, 0xFF, 0xFB, 0xF7, 0x5F, 0xFF, 0xFF, 0xFF,
    0xFF, 0xFF, 0xFF, 0xFF, 0xF7, 0xFF, 0xFC, 0x00, 0x1F, 0xFF, 0xF9, 0xEE, 0xFF, 0xFF, 0xFF, 0xFF,
    0xFF, 0xFF, 0xFF, 0xFF, 0xE7, 0xFF, 0xFF, 0xFF, 0xFF, 0xFF, 0xFD, 0xDD, 0xFF, 0xFF, 0xFF, 0xFF,
    0xFF, 0xFF, 0xFF, 0xFF, 0xEF, 0xF0, 0xFF, 0xFF, 0xFF, 0x87, 0xFE, 0xBF, 0xFF, 0xFF, 0xFF, 0xFF,
    0xFF, 0xFF, 0xFF, 0xFF, 0xEF, 0xFE, 0x1F, 0xFF, 0xFE, 0x1E, 0x9E, 0xFF, 0xFF, 0xFF, 0xFF, 0xFF,
    0xFF, 0xFF, 0xE9, 0x24, 0xAF, 0x40, 0x0F, 0xE0, 0xF0, 0x02, 0x5E, 0x7F, 0xFF, 0xFF, 0xFF, 0xFF,
    0xFF, 0xFF, 0x47, 0x49, 0x26, 0x98, 0x0F, 0xEC, 0xFF, 0x0F, 0x24, 0x88, 0x00, 0x7F, 0xFF, 0xFF,
    0xFF, 0xFA, 0xB4, 0xBC, 0x91, 0x2B, 0xFF, 0xE1, 0xFF, 0xF3, 0xFD, 0x65, 0xBF, 0x9F, 0xFF, 0xFF,
    0xFF, 0xD4, 0x8F, 0xE5, 0x4A, 0x53, 0xFF, 0xF3, 0xFF, 0xFF, 0xFF, 0x3F, 0xE7, 0xDF, 0xFF, 0xFF,
    0xFF, 0x75, 0xFF, 0xBB, 0xEF, 0xBF, 0xFF, 0xFF, 0xFF, 0xFF, 0xFF, 0x9F, 0xF8, 0xEF, 0xFF, 0xFF,
    0xFF, 0x13, 0xFF, 0x77, 0xF9, 0x40, 0x00, 0x00, 0x00, 0x00, 0xFF, 0xB7, 0xFF, 0x6F, 0xFF, 0xFF,
    0xFF, 0xFF, 0xFD, 0xEF, 0xF7, 0x2A, 0xAF, 0xFA, 0xAF, 0x54, 0xFF, 0xBB, 0xFF, 0xDF, 0xFF, 0xFF,
    0xFF, 0xFF, 0xFB, 0xEF, 0xEE, 0xBB, 0x77, 0xFF, 0xFF, 0xEE, 0xF7, 0xBD, 0xF9, 0xFF, 0xFF, 0xFF,
    0xFF, 0xFF, 0xF7, 0xDF, 0xEE, 0x7F, 0xFF, 0xE0, 0x0F, 0xFC, 0xFB, 0xBE, 0x7E, 0xFF, 0xFF, 0xFF,
    0xFF, 0xFF, 0xEF, 0xBF, 0xDE, 0x7F, 0xFE, 0x00, 0x01, 0xFE, 0xFD, 0xBF, 0xFE, 0xFF, 0xFF, 0xFF,
    0xFF, 0xFF, 0xEF, 0xB3, 0xDD, 0x7F, 0xF0, 0x01, 0x00, 0x7C, 0xFD, 0xBD, 0xBA, 0xFF, 0xFF, 0xFF,
    0xFF, 0xFF, 0xDF, 0x7D, 0xDB, 0x7F, 0x80, 0x10, 0x20, 0x3E, 0xFE, 0xBD, 0xDF, 0xFF, 0xFF, 0xFF,
    0xFF, 0xFE, 0xDE, 0xF3, 0xBB, 0x7E, 0x01, 0x04, 0x88, 0x8E, 0xFE, 0xBD, 0xEF, 0xFB, 0xFF, 0xFF,
    0xFF, 0xFF, 0xBE, 0xF7, 0xB7, 0x7F, 0xC4, 0x40, 0x02, 0xFE, 0xFF, 0xBF, 0xEF, 0xFF, 0xFF, 0xFF,
    0xFF, 0xFF, 0xBD, 0xF3, 0xAF, 0x7F, 0xC0, 0x12, 0x20, 0xFE, 0xFF, 0xBD, 0xEF, 0xFF, 0xFF, 0xFF,
    0xFF, 0xFF, 0xFB, 0x7F, 0xAB, 0x0F, 0xC9, 0x00, 0x84, 0x30, 0xFF, 0x5D, 0xB7, 0xFF, 0xFF, 0xFF,
    0xFF, 0xFF, 0xFA, 0xFF, 0xDB, 0x80, 0x00, 0x22, 0x00, 0x00, 0x7E, 0x6D, 0x7B, 0xFF, 0xFF, 0xFF,
    0xFF, 0xFF, 0xF6, 0xFF, 0x9B, 0x80, 0x02, 0x08, 0x24, 0x00, 0x7E, 0xEE, 0x7D, 0xFF, 0xFF, 0xFF,
    0xFF, 0xFF, 0xED, 0xE4, 0xFB, 0x92, 0x20, 0x40, 0x00, 0x92, 0x7C, 0xEF, 0xFD, 0xFF, 0xFF, 0xFF,
    0xFF, 0xFF, 0xEB, 0xDE, 0xFB, 0x80, 0x89, 0x02, 0x48, 0x00, 0x79, 0xF7, 0xF6, 0xFF, 0xFF, 0xFF,
    0xFF, 0xDF, 0xD7, 0xDA, 0xFB, 0x84, 0x03, 0x10, 0x02, 0x48, 0x3B, 0xB7, 0xF6, 0xFF, 0xFF, 0xFF,
    0xFF, 0xFF, 0xD7, 0xEF, 0xFB, 0xC0, 0x27, 0x02, 0x40, 0x02, 0x3B, 0xFB, 0xF9, 0x7F, 0xFF, 0xFF,
    0xFF, 0xFF, 0x4F, 0xFF, 0xFB, 0xC9, 0x05, 0x20, 0x01, 0x20, 0x3B, 0xFB, 0xFE, 0xFF, 0xFF, 0xFF,
    0xFF, 0xFF, 0xFF, 0xFF, 0xFB, 0xC0, 0x0E, 0x00, 0x38, 0x04, 0xBB, 0xFD, 0xFE, 0x7F, 0xFF, 0xFF,
    0xFF, 0xFF, 0xFE, 0x3F, 0xFB, 0xE2, 0x4B, 0xC3, 0xB8, 0x40, 0x3B, 0xDD, 0xFD, 0xFF, 0xFF, 0xFF,
    0xFF, 0xFF, 0xFF, 0xDF, 0xFB, 0xE0, 0x1E, 0x59, 0xF9, 0x08, 0x1B, 0xBD, 0xFF, 0xFF, 0xFF, 0xFF,
    0xFF, 0xFF, 0xFF, 0xBF, 0xFB, 0xF2, 0x08, 0x1E, 0x70, 0x02, 0x9B, 0xFF, 0xDF, 0xFF, 0x7F, 0xFF,
    0xFF, 0xBF, 0xFF, 0x7F, 0xF9, 0xF0, 0x80, 0x27, 0x10, 0x48, 0x1B, 0x7D, 0xFF, 0xFF, 0xFF, 0xFF,
    0xFF, 0xFF, 0xFD, 0x7F, 0xFD, 0xF8, 0x01, 0x63, 0xC1, 0x00, 0x1B, 0xFE, 0xFF, 0xFF, 0xFF, 0xFF,
    0xFF, 0xFF, 0xFC, 0xFF, 0xFD, 0xF8, 0x48, 0xC9, 0xF0, 0x11, 0x5B, 0xFE, 0xFF, 0xFF, 0xFF, 0xFF,
    0xFF, 0xFF, 0xFF, 0xFF, 0xFD, 0xFC, 0x00, 0xDC, 0xFC, 0x40, 0x1B, 0xFE, 0xFE, 0xFF, 0xFF, 0xFF,
    0xFF, 0xFF, 0xFF, 0xFF, 0xFC, 0xFE, 0x49, 0x9F, 0x3F, 0x04, 0x1B, 0xFB, 0xFF, 0xFF, 0xFF, 0xFF,
    0xFF, 0xFF, 0xFF, 0xFF, 0xFE, 0xFF, 0x03, 0x3F, 0x9F, 0xE0, 0x9B, 0xF8, 0xFF, 0xFF, 0xFF, 0xFF,
    0xFF, 0xFF, 0xFF, 0xFF, 0xFE, 0x7F, 0x06, 0x7F, 0xE3, 0xF8, 0x3B, 0xFE, 0xFF, 0xFF, 0xFF, 0xFF,
    0xFF, 0xFF, 0xFF, 0xFF, 0xFF, 0x3F, 0x86, 0xFF, 0xF8, 0x7F, 0x3B, 0xFF, 0xFF, 0xFF, 0xFF, 0xFF,
    0xFF, 0xFF, 0xFF, 0xFF, 0xFF, 0x9F, 0xCC, 0xFF, 0xFF, 0x03, 0xFB, 0xFF, 0xFF, 0xFF, 0xFF, 0xFF,
    0xFF, 0xFF, 0xFF, 0xFF, 0xFF, 0xCF, 0xF9, 0xFF, 0xFF, 0xFC, 0x03, 0xFF, 0xFF, 0xFF, 0xFF, 0xFF,
    0xFF, 0xFF, 0xFF, 0xFF, 0xFF, 0xE7, 0xF3, 0xFF, 0xFF, 0xFF, 0xFF, 0xFF, 0xFF, 0xFF, 0xFF, 0xFF,
    0xFF, 0xFF, 0xFF, 0xFF, 0xFF, 0xF3, 0xC7, 0xFF, 0xFF, 0xFF, 0xFF, 0xFF, 0xFF, 0xFF, 0xFF, 0xFF,
    0xFF, 0xFF, 0xFF, 0xFF, 0xFF, 0xF9, 0x1F, 0xFF, 0xFF, 0xFF, 0xFF, 0xFF, 0xFF, 0xFF, 0xFF, 0xFF,
    0xFF, 0xFF, 0xFF, 0xFF, 0xFF, 0xFC, 0x7F, 0xFF, 0xFF, 0xFF, 0xFF, 0xFF, 0xFF, 0xFF, 0xFF, 0xFF
};

const unsigned char image_data_happy_1[] = {
    0xFF, 0xFF, 0xFF, 0xFF, 0xFF, 0xFF, 0xFF, 0xFF, 0xFF, 0xFF, 0xFF, 0xFF, 0xFF, 0xFF, 0xFF, 0xFF,
    0xFF, 0xFF, 0xFF, 0xFF, 0xFF, 0xFF, 0xFF, 0xFF, 0xFF, 0xFF, 0xFF, 0xFF, 0xFF, 0xFF, 0xFF, 0xFF,
    0xFF, 0xFF, 0xFF, 0xFF, 0xFF, 0xFF, 0xFF, 0xFF, 0xFF, 0xFF, 0xFF, 0xFF, 0xFF, 0xFF, 0xFF, 0xFF,
    0xFF, 0xFF, 0xFF, 0xFF, 0xFF, 0xFF, 0xFF, 0xFF, 0xFF, 0xFF, 0xFF, 0xFF, 0xFF, 0xFF, 0xFF, 0xFF,
    0xFF, 0xFF, 0xFF, 0xFF, 0xFF, 0xFF, 0xFF, 0xFF, 0xFF, 0xFF, 0xFF, 0xFF, 0xFF, 0xFF, 0xFF, 0xFF,
    0xFF, 0xFF, 0xFF, 0xFF, 0xFF, 0xFF, 0xFF, 0xFF, 0xFF, 0xFF, 0xFF, 0xFF, 0xFF, 0xFF, 0xFF, 0xFF,
    0xFF, 0xFF, 0xFF, 0xFF, 0xFF, 0xFF, 0xFF, 0xFF, 0xFF, 0xFF, 0xFF, 0xFF, 0xFF, 0xFF, 0xFF, 0xFF,
    0xFF, 0xFF, 0xFF, 0xFF, 0xFF, 0xFF, 0xFF, 0xFF, 0xFF, 0xFF, 0xFF, 0xFF, 0xFF, 0xFF, 0xFF, 0xFF,
    0xFF, 0xFF, 0xFF, 0xFF, 0xFF, 0xFF, 0xFF, 0xFF, 0xFF, 0xFF, 0xFF, 0xFF, 0xFF, 0xFF, 0xFF, 0xFF,
    0xFF, 0xFF, 0xFF, 0xFF, 0xFF, 0xFF, 0xFF, 0xFF, 0xFF, 0xE1, 0xFF, 0xFF, 0xFF, 0xFF, 0xFF, 0xFF,
    0xFF, 0xFF, 0xFF, 0xFF, 0xFF, 0xBF, 0xFF, 0xFF, 0xFF, 0xCC, 0xFF, 0xFF, 0xFF, 0xFF, 0xFF, 0xFF,
    0xFF, 0xF0, 0xFF, 0xFF, 0xFF, 0x07, 0xFF, 0xFF, 0xFF, 0x9E, 0xFF, 0xFF, 0xFF, 0xFF, 0xFF, 0xFF,
    0xFF, 0xF6, 0x07, 0xFF, 0xFF, 0x73, 0xFF, 0xFF, 0xFF, 0x7F, 0x7F, 0xFF, 0xFF, 0xFF, 0xFF, 0xFF,
    0xFF, 0xF6, 0x77, 0xFF, 0xFE, 0xF9, 0xFF, 0xFF, 0xFE, 0xFF, 0x3F, 0xFF, 0x9F, 0x3F, 0xFF, 0xFF,
    0xFF, 0x82, 0x67, 0xFF, 0xFE, 0xFC, 0xFF, 0xFF, 0xFD, 0xFF, 0xBF, 0xFE, 0xAE, 0x9F, 0xFF, 0xFF,
    0xFF, 0x90, 0x8F, 0xFF, 0xFD, 0xFE, 0x7F, 0xFF, 0xF9, 0xFF, 0x9F, 0xFE, 0x15, 0x4F, 0xFF, 0xFF,
    0xFF, 0xDE, 0x8F, 0xFF, 0xFD, 0xFF, 0x3F, 0xFF, 0xFB, 0xFF, 0xDF, 0xFD, 0x44, 0x27, 0xFF, 0xFF,
    0xFF, 0xC5, 0x67, 0xFF, 0xFD, 0xFF, 0x9F, 0xFF, 0xF3, 0xFF, 0xDF, 0xFE, 0x52, 0x9F, 0xFF, 0xFF,
    0xFF, 0xC2, 0x37, 0xFF, 0xFB, 0xFF, 0xDF, 0xFF, 0xF7, 0xFF, 0xDF, 0xFE, 0x88, 0x4F, 0xFF, 0xFF,
    0xFF, 0x99, 0x07, 0xFF, 0xFB, 0xFF, 0xCF, 0xFF, 0xF7, 0xFF, 0xEF, 0xFF, 0x25, 0x3F, 0xFF, 0xFF,
    0xFF, 0xB1, 0x8F, 0xFF, 0xFB, 0xFF, 0xE8, 0x99, 0x87, 0xFF, 0xEF, 0xFF, 0x90, 0xBF, 0xFF, 0xFF,
    0xFF, 0xA5, 0xBF, 0xFF, 0xFB, 0xFF, 0xE2, 0x02, 0x27, 0xFF, 0xEF, 0xFF, 0xCA, 0x7F, 0xFF, 0xFF,
    0xFF, 0x8D, 0xBF, 0xFF, 0xFB, 0xFF, 0xE6, 0x73, 0x37, 0xFF, 0xE7, 0xFF, 0xE5, 0xFF, 0xFF, 0xFF,
    0xFF, 0xFC, 0x3F, 0xFF, 0xF7, 0xFF, 0xFF, 0xFF, 0xFF, 0xFF, 0xF7, 0xFF, 0xFB, 0xFF, 0xFF, 0xFF,
    0xFF, 0xFF, 0xFF, 0xFF, 0xF7, 0xFF, 0xFF, 0xFF, 0xFF, 0xFF, 0xF7, 0xFF, 0xFF, 0xFF, 0xFF, 0xFF,
    0xFF, 0xFF, 0xFF, 0xFF, 0xF7, 0xFF, 0xFF, 0xFF, 0xFF, 0xFF, 0xF7, 0xFF, 0xFF, 0xFF, 0xFF, 0xFF,
    0xFF, 0xFF, 0xFF, 0xFF, 0xF7, 0xFF, 0xFF, 0xFF, 0xFF, 0xFF, 0xF7, 0xFF, 0xFF, 0xFF, 0xFF, 0xFF,
    0xFF, 0xFF, 0xFF, 0xFF, 0xF7, 0xFF, 0xFF, 0xFF, 0xFF, 0xFF, 0xF7, 0xFF, 0xFF, 0xFF, 0xFF, 0xFF,
    0xFF, 0xFF, 0xFF, 0xFF, 0xF7, 0xFF, 0xFF, 0xFF, 0xFF, 0xFF, 0xF7, 0x7F, 0xFF, 0xFF, 0xFF, 0xFF,
    0xFF, 0xFF, 0xFF, 0xFF, 0xEF, 0xFF, 0xFF, 0xFF, 0xFF, 0xFF, 0xF6, 0x7F, 0xFF, 0xFF, 0xFF, 0xFF,
    0xFF, 0xFF, 0xFF, 0xFF, 0xEF, 0xFF, 0xCF, 0xFF, 0xF3, 0xFF, 0xF6, 0xFF, 0xFF, 0xFF, 0xFF, 0xFF,
    0xFF, 0xFF, 0xFF, 0xFF, 0xEF, 0xFF, 0xCF, 0xFF, 0xF3, 0xFF, 0xFC, 0xBF, 0xFF, 0xFF, 0xFF, 0xFF,
    0xFF, 0xFF, 0xFF, 0xEF, 0xEF, 0xFF, 0xCF, 0xFF, 0xF3, 0xFF, 0xF9, 0x3F, 0xFF, 0xFF, 0xFF, 0xFF,
    0xFF, 0xFF, 0xFF, 0xE0, 0x1F, 0xFF, 0xCF, 0xFF, 0xF3, 0xFF, 0xF4, 0x7F, 0xFF, 0xFF, 0xFF, 0xFF,
    0xFF, 0xFF, 0xFF, 0xFF, 0xFF, 0xFF, 0xCF, 0xFF, 0xF3, 0xFF, 0xF1, 0xFF, 0xFE, 0x3F, 0xFF, 0xFF,
    0xFF, 0xFF, 0xFF, 0xE0, 0x1F, 0xFF, 0xCF, 0xFF, 0xF3, 0xFF, 0xFF, 0xFF, 0xE0, 0xBF, 0xFF, 0xFF,
    0xFF, 0xFF, 0xFF, 0xFF, 0xC7, 0xFF, 0xCF, 0xFF, 0xF3, 0xFF, 0xFF, 0xCF, 0xE9, 0x9F, 0xFF, 0xFF,
    0xFF, 0xFF, 0xFF, 0xFC, 0x1F, 0xFF, 0xFF, 0xC7, 0xFF, 0xFF, 0xE0, 0x1F, 0xE8, 0xDF, 0xFF, 0xFF,
    0xFF, 0xFF, 0xFF, 0xFD, 0xDF, 0xF5, 0xFF, 0xE7, 0xFF, 0x5F, 0xEF, 0xFF, 0x86, 0xBF, 0xFF, 0xFF,
    0xFF, 0xFF, 0xFF, 0xFF, 0xDB, 0xEB, 0xFF, 0xFF, 0xFE, 0xBF, 0xE7, 0xFF, 0x32, 0x07, 0xFF, 0xFF,
    0xFF, 0xFF, 0xFF, 0xFF, 0x3B, 0xFF, 0xFF, 0xEF, 0xFF, 0xFF, 0xF0, 0x7F, 0x78, 0xF3, 0xFF, 0xFF,
    0xFF, 0xFF, 0xFF, 0xFE, 0x77, 0xFF, 0xFB, 0xD7, 0xBF, 0xFF, 0xCF, 0xFF, 0x38, 0x03, 0xFF, 0xFF,
    0xFF, 0xFF, 0xFF, 0xFC, 0xEF, 0xFF, 0xFC, 0x38, 0x7F, 0xFF, 0xE3, 0xFF, 0x82, 0x8F, 0xFF, 0xFF,
    0xFF, 0xFF, 0xFF, 0xFF, 0x9F, 0xFF, 0xFF, 0xFF, 0xFF, 0xFF, 0xF0, 0xFF, 0xF6, 0xDF, 0xFF, 0xFF,
    0xFF, 0xFF, 0xFF, 0xFE, 0x37, 0xFF, 0xFF, 0xFF, 0xFF, 0xFF, 0xE7, 0xFF, 0xE4, 0x4F, 0xFF, 0xFF,
    0xFF, 0xFF, 0xFF, 0xFE, 0xF3, 0xFF, 0xFF, 0xFF, 0xFF, 0xFF, 0xEF, 0xFF, 0xED, 0x2F, 0xFF, 0xFF,
    0xFF, 0xFF, 0xFF, 0xFF, 0xF9, 0xFF, 0xFF, 0xFF, 0xFF, 0xFF, 0xCF, 0xFF, 0xED, 0x8F, 0xFF, 0xFF,
    0xFF, 0xFF, 0xFF, 0xFF, 0xFC, 0x7F, 0xFF, 0xFF, 0xFF, 0xFF, 0x9F, 0xFF, 0xF1, 0xFF, 0xFF, 0xFF,
    0xFF, 0xFF, 0x3E, 0x7F, 0xFF, 0x1F, 0xFF, 0xFF, 0xFF, 0xFF, 0x3F, 0xFF, 0xFF, 0xFF, 0xFF, 0xFF,
    0xFF, 0xFD, 0x5D, 0x3F, 0xFF, 0xE7, 0xFF, 0xFF, 0xFF, 0xFC, 0x7F, 0xFF, 0xFF, 0xFF, 0xFF, 0xFF,
    0xFF, 0xFC, 0x2A, 0x9F, 0xFF, 0xF8, 0x00, 0x00, 0x00, 0x03, 0xFF, 0xFF, 0xFF, 0xFF, 0xFF, 0xFF,
    0xFF, 0xFA, 0x88, 0x4F, 0xFF, 0xFF, 0xFF, 0xFF, 0xFF, 0xFF, 0xFF, 0xFF, 0xFF, 0xFF, 0xFF, 0xFF,
    0xFF, 0xFC, 0xA5, 0x3F, 0xFF, 0xFF, 0xFF, 0xFF, 0xFF, 0xFF, 0xFF, 0xFF, 0xFF, 0xFF, 0xFF, 0xFF,
    0xFF, 0xFD, 0x10, 0x9F, 0xFF, 0xFF, 0xFF, 0xFF, 0xFF, 0xFF, 0xFF, 0xFF, 0xFF, 0xFF, 0xFF, 0xFF,
    0xFF, 0xFE, 0x4A, 0x7F, 0xFF, 0xFF, 0xFF, 0xFF, 0xFF, 0xFF, 0xFF, 0xFF, 0xFF, 0xFF, 0xFF, 0xFF,
    0xFF, 0xFF, 0x21, 0x7F, 0xFF, 0xFF, 0xFF, 0xFF, 0xFF, 0xFF, 0xFF, 0xFF, 0xFF, 0xFF, 0xFF, 0xFF,
    0xFF, 0xFF, 0x94, 0xFF, 0xFF, 0xFF, 0xFF, 0xFF, 0xFF, 0xFF, 0xFF, 0xFF, 0xFF, 0xFF, 0xFF, 0xFF,
    0xFF, 0xFF, 0xCB, 0xFF, 0xFF, 0xFF, 0xFF, 0xFF, 0xFF, 0xFF, 0xFF, 0xFF, 0xFF, 0xFF, 0xFF, 0xFF,
    0xFF, 0xFF, 0xF7, 0xFF, 0xFF, 0xFF, 0xFF, 0xFF, 0xFF, 0xFF, 0xFF, 0xFF, 0xFF, 0xFF, 0xFF, 0xFF,
    0xFF, 0xFF, 0xFF, 0xFF, 0xFF, 0xFF, 0xFF, 0xFF, 0xFF, 0xFF, 0xFF, 0xFF, 0xFF, 0xFF, 0xFF, 0xFF,
    0xFF, 0xFF, 0xFF, 0xFF, 0xFF, 0xFF, 0xFF, 0xFF, 0xFF, 0xFF, 0xFF, 0xFF, 0xFF, 0xFF, 0xFF, 0xFF,
    0xFF, 0xFF, 0xFF, 0xFF, 0xFF, 0xFF, 0xFF, 0xFF, 0xFF, 0xFF, 0xFF, 0xFF, 0xFF, 0xFF, 0xFF, 0xFF,
    0xFF, 0xFF, 0xFF, 0xFF, 0xFF, 0xFF, 0xFF, 0xFF, 0xFF, 0xFF, 0xFF, 0xFF, 0xFF, 0xFF, 0xFF, 0xFF,
    0xFF, 0xFF, 0xFF, 0xFF, 0xFF, 0xFF, 0xFF, 0xFF, 0xFF, 0xFF, 0xFF, 0xFF, 0xFF, 0xFF, 0xFF, 0xFF
};

const unsigned char image_data_happy_2[] = {
    0xFF, 0xFF, 0xFF, 0xFF, 0xFF, 0xFF, 0xFF, 0xFF, 0xFF, 0xFF, 0xFF, 0xFF, 0xFF, 0xFF, 0xFF, 0xFF,
    0xFF, 0xFF, 0xFF, 0xFF, 0xFF, 0xFF, 0xFF, 0xFF, 0xFF, 0xFF, 0xFF, 0xFF, 0xFF, 0xFF, 0xFF, 0xFF,
    0xFF, 0xFF, 0xFF, 0xFF, 0xFF, 0xFF, 0xFF, 0xFF, 0xFF, 0xFF, 0xFF, 0xFF, 0xFF, 0xFF, 0xFF, 0xFF,
    0xFF, 0xFF, 0xFF, 0xFF, 0xFF, 0xFF, 0xFF, 0xFF, 0xFF, 0xFF, 0xFF, 0xFF, 0xFF, 0xFF, 0xFF, 0xFF,
    0xFF, 0xFF, 0xFF, 0xFF, 0xFF, 0xFF, 0xFF, 0xFF, 0xFF, 0xFF, 0xFF, 0xFF, 0xFF, 0xFF, 0xFF, 0xFF,
    0xFF, 0xFF, 0xFF, 0xFF, 0xFF, 0xFF, 0xFF, 0xFF, 0xFF, 0xFF, 0xFF, 0xFF, 0xFF, 0xFF, 0xFF, 0xFF,
    0xFF, 0xFF, 0xFF, 0xFF, 0xFF, 0xFF, 0xFF, 0xFF, 0xFF, 0xFF, 0xFF, 0xFF, 0xFF, 0xFF, 0xFF, 0xFF,
    0xFF, 0xFF, 0xFF, 0xFF, 0xFF, 0xFF, 0xFF, 0xFF, 0xFF, 0xFD, 0xFF, 0xFF, 0xFF, 0xFF, 0xFF, 0xFF,
    0xFF, 0xFF, 0xFF, 0xFF, 0xFF, 0xFF, 0xFF, 0xFF, 0xFF, 0xF1, 0xFF, 0xFF, 0xFF, 0xFF, 0xFF, 0xFF,
    0xFF, 0xFE, 0x1F, 0xFF, 0xFF, 0xFF, 0xFF, 0xFF, 0xFF, 0xE6, 0xFF, 0xFF, 0xFF, 0xFF, 0xFF, 0xFF,
    0xFF, 0xFE, 0xC0, 0xFF, 0xFF, 0x8F, 0xFF, 0xFF, 0xFF, 0x8F, 0x7F, 0xFF, 0xFF, 0xFF, 0xFF, 0xFF,
    0xFF, 0xFE, 0xCE, 0xFF, 0xFF, 0xB3, 0xFF, 0xFF, 0xFF, 0x3F, 0x7F, 0xFF, 0xFF, 0xFF, 0xFF, 0xFF,
    0xFF, 0xF0, 0x4C, 0xFF, 0xFF, 0x79, 0xFF, 0xFF, 0xFE, 0xFF, 0xBF, 0xFF, 0xE7, 0xCF, 0xFF, 0xFF,
    0xFF, 0xF2, 0x11, 0xFF, 0xFE, 0x7E, 0xFF, 0xFF, 0xF9, 0xFF, 0xBF, 0xFF, 0xAB, 0xA7, 0xFF, 0xFF,
    0xFF, 0xFB, 0xD1, 0xFF, 0xFD, 0xFF, 0x3F, 0xFF, 0xFB, 0xFF, 0xBF, 0xFF, 0x85, 0x53, 0xFF, 0xFF,
    0xFF, 0xF8, 0xAC, 0xFF, 0xFD, 0xFF, 0x9F, 0xFF, 0xF7, 0xFF, 0xDF, 0xFF, 0x51, 0x09, 0xFF, 0xFF,
    0xFF, 0xF8, 0x46, 0xFF, 0xFB, 0xFF, 0xDF, 0xFF, 0xF7, 0xFF, 0xDF, 0xFF, 0x94, 0xA7, 0xFF, 0xFF,
    0xFF, 0xF3, 0x20, 0xFF, 0xFB, 0xFF, 0xEF, 0xFF, 0xEF, 0xFF, 0xDF, 0xFF, 0xA2, 0x13, 0xFF, 0xFF,
    0xFF, 0xF6, 0x31, 0xFF, 0xF7, 0xFF, 0xEF, 0xCF, 0xEF, 0xFF, 0xEF, 0xFF, 0xC9, 0x67, 0xFF, 0xFF,
    0xFF, 0xF4, 0xB7, 0xFF, 0xF7, 0xFF, 0xF7, 0xCE, 0xEF, 0xFF, 0xEF, 0xFF, 0xE4, 0x2F, 0xFF, 0xFF,
    0xFF, 0xF1, 0xB7, 0xFF, 0xF7, 0xFF, 0xF0, 0x24, 0x0F, 0xFF, 0xE7, 0xFF, 0xF2, 0x9F, 0xFF, 0xFF,
    0xFF, 0xFF, 0x87, 0xFF, 0xEF, 0xFF, 0xF3, 0x31, 0x0F, 0xFF, 0xF7, 0xFF, 0xF9, 0x3F, 0xFF, 0xFF,
    0xFF, 0xFF, 0xFF, 0xFF, 0xEF, 0xFF, 0xFF, 0xFF, 0xFF, 0xFF, 0xF3, 0xFF, 0xFE, 0xFF, 0xFF, 0xFF,
    0xFF, 0xFF, 0xFF, 0xFF, 0xEF, 0xFF, 0xFF, 0xFF, 0xFF, 0xFF, 0xFB, 0xFF, 0xFF, 0xFF, 0xFF, 0xFF,
    0xFF, 0xFF, 0xFF, 0xFF, 0xEF, 0xFF, 0xFF, 0xFF, 0xFF, 0xFF, 0xFB, 0xFF, 0xFF, 0xFF, 0xFF, 0xFF,
    0xFF, 0xFF, 0xFF, 0xFF, 0xEF, 0xFF, 0xFF, 0xFF, 0xFF, 0xFF, 0xFB, 0xFF, 0xFF, 0xFF, 0xFF, 0xFF,
    0xFF, 0xFF, 0xFF, 0xFF, 0xEF, 0xFF, 0xFF, 0xFF, 0xFF, 0xFF, 0xF9, 0xFF, 0xFF, 0xFF, 0xFF, 0xFF,
    0xFF, 0xFF, 0xFF, 0xFF, 0xEF, 0xFF, 0xFF, 0xFF, 0xFF, 0xFF, 0xFD, 0xFF, 0xFF, 0xFF, 0xFF, 0xFF,
    0xFF, 0xFF, 0xFF, 0xFF, 0xEF, 0xFF, 0xFF, 0xFF, 0xFF, 0xFF, 0xFD, 0xFF, 0xFF, 0xFF, 0xFF, 0xFF,
    0xFF, 0xFF, 0xFF, 0xFF, 0xEF, 0xFF, 0xFF, 0xFF, 0xFF, 0xFF, 0xF8, 0xFF, 0xFF, 0xFF, 0xFF, 0xFF,
    0xFF, 0xFF, 0xFF, 0xFF, 0xEF, 0xFF, 0xCF, 0xFF, 0xF3, 0xFF, 0xFC, 0xFF, 0xFF, 0xFF, 0xFF, 0xFF,
    0xFF, 0xFF, 0xFF, 0xF3, 0xEF, 0xFF, 0xCF, 0xFF, 0xF3, 0xFF, 0xF9, 0xFF, 0xFF, 0xFF, 0xFF, 0xFF,
    0xFF, 0xFF, 0xFF, 0xF8, 0x0F, 0xFF, 0xCF, 0xFF, 0xF3, 0xFF, 0xF3, 0xFF, 0xFF, 0xFF, 0xFF, 0xFF,
    0xFF, 0xFF, 0xFF, 0xFF, 0x8F, 0xFF, 0xCF, 0xFF, 0xF3, 0xFF, 0xFF, 0x7F, 0xFF, 0x8F, 0xFF, 0xFF,
    0xFF, 0xFF, 0xFF, 0xC0, 0x3F, 0xFF, 0xCF, 0xFF, 0xF3, 0xFF, 0xF0, 0x7F, 0xF8, 0x2F, 0xFF, 0xFF,
    0xFF, 0xFF, 0xFF, 0xFF, 0xFF, 0xFF, 0xCF, 0xFF, 0xF3, 0xFF, 0xE0, 0x3F, 0xFA, 0x67, 0xFF, 0xFF,
    0xFF, 0xFF, 0xFF, 0xFF, 0x9F, 0xFF, 0xCF, 0xFF, 0xF3, 0xFF, 0xFF, 0xFF, 0xFA, 0x37, 0xFF, 0xFF,
    0xFF, 0xFF, 0xFF, 0xE0, 0x5F, 0xFF, 0xFF, 0xC7, 0xFF, 0xFF, 0xFE, 0x7F, 0xE1, 0xAF, 0xFF, 0xFF,
    0xFF, 0xFF, 0xFF, 0xFF, 0x9F, 0xE7, 0xFF, 0xE7, 0xFE, 0x7F, 0xF8, 0xFF, 0xCC, 0x81, 0xFF, 0xFF,
    0xFF, 0xFF, 0xFF, 0xFF, 0x3F, 0xD7, 0xFF, 0xFF, 0xFD, 0x7F, 0xE3, 0xBF, 0xDE, 0x3C, 0xFF, 0xFF,
    0xFF, 0xFF, 0xFF, 0xFE, 0x7F, 0xFF, 0xFF, 0xEF, 0xFF, 0xFF, 0x80, 0x3F, 0xCE, 0x00, 0xFF, 0xFF,
    0xFF, 0xFF, 0xFF, 0xFF, 0xDF, 0xFF, 0xFD, 0xD7, 0x7F, 0xFF, 0xC7, 0xFF, 0xE0, 0xA3, 0xFF, 0xFF,
    0xFF, 0xFF, 0xFF, 0xFF, 0x1F, 0xFF, 0xFC, 0x38, 0x7F, 0xFF, 0xF0, 0x7F, 0xFD, 0xB7, 0xFF, 0xFF,
    0xFF, 0xFF, 0xFF, 0xE0, 0x4F, 0xFF, 0xFF, 0xFF, 0xFF, 0xFF, 0xEF, 0xFF, 0xF9, 0x13, 0xFF, 0xFF,
    0xFF, 0xFF, 0xFF, 0xFF, 0xD3, 0xFF, 0xFF, 0xFF, 0xFF, 0xFF, 0xCF, 0xFF, 0xFB, 0x4B, 0xFF, 0xFF,
    0xFF, 0xFF, 0xFF, 0xFF, 0xD9, 0xFF, 0xFF, 0xFF, 0xFF, 0xFF, 0x9F, 0xFF, 0xFB, 0x63, 0xFF, 0xFF,
    0xFF, 0xF9, 0xF3, 0xFF, 0xFC, 0xFF, 0xFF, 0xFF, 0xFF, 0xFF, 0x3F, 0xFF, 0xFC, 0x7F, 0xFF, 0xFF,
    0xFF, 0xEA, 0xE9, 0xFF, 0xFE, 0x7F, 0xFF, 0xFF, 0xFF, 0xF8, 0xFF, 0xFF, 0xFF, 0xFF, 0xFF, 0xFF,
    0xFF, 0xE1, 0x54, 0xFF, 0xFF, 0x1F, 0xFF, 0xFF, 0xFF, 0x83, 0xFF, 0xFF, 0xFF, 0xFF, 0xFF, 0xFF,
    0xFF, 0xD4, 0x42, 0x7F, 0xFF, 0xC3, 0xFF, 0xFF, 0xF8, 0x3F, 0xFF, 0xFF, 0xFF, 0xFF, 0xFF, 0xFF,
    0xFF, 0xE5, 0x29, 0xFF, 0xFF, 0xF8, 0x07, 0xFE, 0x03, 0xFF, 0xFF, 0xFF, 0xFF, 0xFF, 0xFF, 0xFF,
    0xFF, 0xE8, 0x84, 0xFF, 0xFF, 0xFF, 0xF8, 0x00, 0xFF, 0xFF, 0xFF, 0xFF, 0xFF, 0xFF, 0xFF, 0xFF,
    0xFF, 0xF2, 0x59, 0xFF, 0xFF, 0xFF, 0xFF, 0xFF, 0xFF, 0xFF, 0xFF, 0xFF, 0xFF, 0xFF, 0xFF, 0xFF,
    0xFF, 0xF9, 0x0B, 0xFF, 0xFF, 0xFF, 0xFF, 0xFF, 0xFF, 0xFF, 0xFF, 0xFF, 0xFF, 0xFF, 0xFF, 0xFF,
    0xFF, 0xFC, 0xA7, 0xFF, 0xFF, 0xFF, 0xFF, 0xFF, 0xFF, 0xFF, 0xFF, 0xFF, 0xFF, 0xFF, 0xFF, 0xFF,
    0xFF, 0xFE, 0x4F, 0xFF, 0xFF, 0xFF, 0xFF, 0xFF, 0xFF, 0xFF, 0xFF, 0xFF, 0xFF, 0xFF, 0xFF, 0xFF,
    0xFF, 0xFF, 0xBF, 0xFF, 0xFF, 0xFF, 0xFF, 0xFF, 0xFF, 0xFF, 0xFF, 0xFF, 0xFF, 0xFF, 0xFF, 0xFF,
    0xFF, 0xFF, 0xFF, 0xFF, 0xFF, 0xFF, 0xFF, 0xFF, 0xFF, 0xFF, 0xFF, 0xFF, 0xFF, 0xFF, 0xFF, 0xFF,
    0xFF, 0xFF, 0xFF, 0xFF, 0xFF, 0xFF, 0xFF, 0xFF, 0xFF, 0xFF, 0xFF, 0xFF, 0xFF, 0xFF, 0xFF, 0xFF,
    0xFF, 0xFF, 0xFF, 0xFF, 0xFF, 0xFF, 0xFF, 0xFF, 0xFF, 0xFF, 0xFF, 0xFF, 0xFF, 0xFF, 0xFF, 0xFF,
    0xFF, 0xFF, 0xFF, 0xFF, 0xFF, 0xFF, 0xFF, 0xFF, 0xFF, 0xFF, 0xFF, 0xFF, 0xFF, 0xFF, 0xFF, 0xFF,
    0xFF, 0xFF, 0xFF, 0xFF, 0xFF, 0xFF, 0xFF, 0xFF, 0xFF, 0xFF, 0xFF, 0xFF, 0xFF, 0xFF, 0xFF, 0xFF,
    0xFF, 0xFF, 0xFF, 0xFF, 0xFF, 0xFF, 0xFF, 0xFF, 0xFF, 0xFF, 0xFF, 0xFF, 0xFF, 0xFF, 0xFF, 0xFF,
    0xFF, 0xFF, 0xFF, 0xFF, 0xFF, 0xFF, 0xFF, 0xFF, 0xFF, 0xFF, 0xFF, 0xFF, 0xFF, 0xFF, 0xFF, 0xFF
};

const unsigned char image_data_dying_1[] = {
    0xFF, 0xFF, 0xFF, 0xFF, 0xFF, 0xFF, 0xFF, 0xFF, 0xFF, 0xFF, 0xFF, 0xFF, 0xFF, 0xFF, 0xFF, 0xFF,
    0xFF, 0xFF, 0xFF, 0xFF, 0xFF, 0xFF, 0xFF, 0xFF, 0xFF, 0xFF, 0xFF, 0xFF, 0xFF, 0xFF, 0xFF, 0xFF,
    0xFF, 0xFF, 0xFF, 0xFF, 0xFF, 0xFF, 0xFF, 0xFF, 0xFF, 0xFF, 0xFF, 0xFF, 0xFF, 0xFF, 0xFF, 0xFF,
    0xFF, 0xFF, 0xFF, 0xFF, 0xFF, 0xFF, 0xFF, 0xFF, 0xFF, 0xFF, 0xFF, 0xFF, 0xFF, 0xFF, 0xFF, 0xFF,
    0xFF, 0xFF, 0xFF, 0xFF, 0xFF, 0xFF, 0xFF, 0xFF, 0xFF, 0xFF, 0xFF, 0xFF, 0xFF, 0xFF, 0xFF, 0xFF,
    0xFF, 0xFF, 0xFF, 0xFF, 0xFF, 0xFF, 0xFF, 0xFF, 0xFF, 0xFF, 0xFF, 0xFF, 0xFF, 0xFF, 0xFF, 0xFF,
    0xFF, 0xFF, 0xFF, 0xFF, 0xFF, 0xFF, 0xFF, 0xFF, 0xFF, 0xFF, 0xFF, 0xFF, 0xFF, 0xFF, 0xFF, 0xFF,
    0xFF, 0xFF, 0xFF, 0xFF, 0xFF, 0xFF, 0xFF, 0xFF, 0xFF, 0xFF, 0xFF, 0xFF, 0xFF, 0xFF, 0xFF, 0xFF,
    0xFF, 0xFF, 0xFF, 0xFF, 0xFF, 0xFF, 0xFF, 0xFF, 0xFF, 0xFF, 0xFF, 0xFF, 0xFF, 0xFF, 0xFF, 0xFF,
    0xFF, 0xFF, 0xFF, 0xFF, 0xFF, 0xFF, 0xFF, 0xFF, 0xFF, 0xFF, 0xFF, 0xFF, 0xFF, 0xFF, 0xFF, 0xFF,
    0xFF, 0xFF, 0xFF, 0xFF, 0xFF, 0xFF, 0xFF, 0xFF, 0xFF, 0xFF, 0xFF, 0xFF, 0xFF, 0xFF, 0xFF, 0xFF,
    0xFF, 0xFF, 0xFF, 0xFF, 0xFF, 0xFF, 0xFF, 0xFF, 0xFF, 0xFF, 0xFF, 0xFF, 0xFF, 0xFF, 0xFF, 0xFF,
    0xFF, 0xFF, 0xFF, 0xFF, 0xFF, 0xFF, 0xFF, 0xFF, 0xFF, 0xFF, 0xFF, 0xFF, 0xFF, 0xFF, 0xFF, 0xFF,
    0xFF, 0xFF, 0xFF, 0xFF, 0xFF, 0xFF, 0xFF, 0xFF, 0xFF, 0xFF, 0xFF, 0xFF, 0xFF, 0xFF, 0xFF, 0xFF,
    0xFF, 0xFF, 0xFF, 0xFF, 0xFF, 0xFF, 0xFF, 0xFF, 0xFF, 0xFF, 0xFF, 0xFF, 0xFF, 0xFF, 0xFF, 0xFF,
    0xFF, 0xFF, 0xFF, 0xFF, 0xFF, 0xFF, 0xFF, 0xFF, 0xFF, 0xFC, 0x0F, 0xFF, 0xFF, 0xFF, 0xFF, 0xFF,
    0xFF, 0xFF, 0xFF, 0xFF, 0x80, 0x00, 0xFF, 0xFF, 0xFF, 0x83, 0xE3, 0xFF, 0xFF, 0xFF, 0xFF, 0xFF,
    0xFF, 0xFF, 0xFF, 0xFF, 0x7F, 0xFE, 0x1F, 0xFF, 0xFC, 0x3F, 0xFB, 0xFF, 0xFF, 0xFF, 0xFF, 0xFF,
    0xFF, 0xFF, 0xFF, 0xFF, 0x7F, 0xFF, 0xCF, 0xFF, 0xF1, 0xFF, 0xDB, 0xFF, 0xFF, 0xFF, 0xFF, 0xFF,
    0xFF, 0xFF, 0xFF, 0xFF, 0x7F, 0xFF, 0xE7, 0xFF, 0xE7, 0xF9, 0x8B, 0xFF, 0xFF, 0xFF, 0xFF, 0xFF,
    0xFF, 0xFF, 0xFF, 0xFE, 0x31, 0xFF, 0xF0, 0x00, 0x4F, 0xF8, 0x25, 0xFF, 0xFF, 0xFF, 0xFF, 0xFF,
    0xFF, 0xFF, 0xFF, 0xFE, 0xFC, 0xFF, 0xFF, 0xFF, 0x3F, 0xFC, 0xF5, 0xFF, 0xFF, 0xFF, 0xFF, 0xFF,
    0xFF, 0xFF, 0xFF, 0xFE, 0x7E, 0x7F, 0xFF, 0xFF, 0xFF, 0xFE, 0xFD, 0xFF, 0xFF, 0xFF, 0xFF, 0xFF,
    0xFF, 0xFF, 0xFF, 0xFE, 0x3F, 0x7F, 0xFF, 0xFF, 0xFF, 0xF9, 0xFD, 0xFF, 0xFF, 0xFF, 0xFF, 0xFF,
    0xFF, 0xFF, 0xFF, 0xFF, 0x9F, 0x7F, 0xFF, 0xFF, 0xFF, 0xFC, 0xFD, 0xFF, 0xFF, 0xFF, 0xFF, 0xFF,
    0xFF, 0xFF, 0xFF, 0xFF, 0xDF, 0x7F, 0xFF, 0xFF, 0xFF, 0xFF, 0x3D, 0xFF, 0xFF, 0xFF, 0xFF, 0xFF,
    0xFF, 0xFF, 0xFF, 0xFF, 0xDF, 0x7F, 0xFF, 0xFF, 0xFF, 0xFE, 0x3D, 0xFF, 0xFF, 0xFF, 0xFF, 0xFF,
    0xFF, 0xFF, 0xFF, 0xFF, 0xDF, 0xFF, 0xFF, 0xFF, 0xFF, 0xFF, 0xFD, 0xFF, 0xFF, 0xFF, 0xFF, 0xFF,
    0xFF, 0xFF, 0xFF, 0xFF, 0xDF, 0xFF, 0xFF, 0xFF, 0xFF, 0xFF, 0xFF, 0xFF, 0xFF, 0xFF, 0xFF, 0xFF,
    0xFF, 0xFF, 0xFF, 0xFF, 0xDF, 0xFF, 0xFF, 0xFF, 0xFF, 0xFF, 0xFF, 0xFF, 0xFF, 0xFF, 0xFF, 0xFF,
    0xFF, 0xFF, 0xFF, 0xFF, 0xDF, 0xFF, 0xFF, 0xFF, 0xFF, 0xFF, 0xF0, 0x7F, 0xFF, 0xFF, 0xFF, 0xFF,
    0xFF, 0xFF, 0xFF, 0xFF, 0xEF, 0xFF, 0xF1, 0xFF, 0x8F, 0xFF, 0xFF, 0x7F, 0xFF, 0xFF, 0xFF, 0xFF,
    0xFF, 0xFF, 0xFF, 0xFE, 0x0F, 0xFF, 0xE3, 0xFF, 0xE7, 0xFF, 0xFF, 0xBF, 0xFF, 0xFF, 0xFF, 0xFF,
    0xFF, 0xFF, 0xFF, 0xF8, 0xFF, 0xFF, 0x8F, 0xFF, 0xF1, 0xFF, 0xFF, 0xBF, 0xFF, 0xFF, 0xFF, 0xFF,
    0xFF, 0xFF, 0xFF, 0xF3, 0x9F, 0xFE, 0x1F, 0xFF, 0xF8, 0xFF, 0xC1, 0xBF, 0xFF, 0xFF, 0xFF, 0xFF,
    0xFF, 0xFF, 0xFF, 0xE7, 0x3F, 0xFE, 0x7F, 0xFF, 0xFE, 0xFF, 0xFC, 0xBF, 0xFF, 0xFF, 0xFF, 0xFF,
    0xFF, 0xFF, 0xFF, 0xEE, 0x7F, 0xFF, 0xFF, 0xFF, 0xFF, 0xFF, 0xFE, 0xBF, 0xFF, 0xFF, 0xFF, 0xFF,
    0xFF, 0xFF, 0xFF, 0xCE, 0xFF, 0xFF, 0xFF, 0xC7, 0xFF, 0xFF, 0xFF, 0x3F, 0xFF, 0xFF, 0xFF, 0xFF,
    0xFF, 0xFF, 0xFF, 0xFE, 0xDF, 0xFF, 0xFF, 0xE7, 0xFF, 0xFF, 0xFF, 0xBF, 0xFF, 0xFF, 0xFF, 0xFF,
    0xFF, 0xFF, 0xFF, 0xFE, 0x9F, 0xFF, 0xFF, 0xFF, 0xFF, 0xFF, 0xE1, 0xBF, 0xFF, 0xFF, 0xFF, 0xFF,
    0xFF, 0xFF, 0xFF, 0xFE, 0x1F, 0xFF, 0xFF, 0xFF, 0xFF, 0xFF, 0xFD, 0xDF, 0xFF, 0xFF, 0xFF, 0xFF,
    0xFF, 0xFF, 0xFF, 0xFE, 0x5F, 0xFF, 0xFF, 0xC3, 0xFF, 0xFF, 0xFC, 0xDF, 0xFF, 0xFF, 0xFF, 0xFF,
    0xFF, 0xFF, 0xFF, 0xFE, 0xDF, 0xFF, 0xFC, 0x18, 0x3F, 0xFF, 0xCE, 0xDF, 0xFF, 0xFF, 0xFF, 0xFF,
    0xFF, 0xFF, 0xFF, 0xFE, 0xC7, 0xFF, 0xFC, 0xFF, 0xBF, 0xFF, 0xEE, 0xCF, 0xFF, 0xFF, 0xFF, 0xFF,
    0xFF, 0xFF, 0xFF, 0xFE, 0xD3, 0xFF, 0xFE, 0x01, 0x3F, 0xFF, 0xE6, 0xEF, 0xFF, 0xFF, 0xFF, 0xFF,
    0xFF, 0xFF, 0xFF, 0xFE, 0xD9, 0xFF, 0xFF, 0xFC, 0x7F, 0xFF, 0xCE, 0xFF, 0xFF, 0xFF, 0xFF, 0xFF,
    0xFF, 0xFF, 0xFF, 0xFE, 0xDC, 0xFF, 0xFF, 0xFE, 0x7F, 0xFF, 0x1F, 0xFF, 0xFF, 0xFF, 0xFF, 0xFF,
    0xFF, 0xFF, 0xFF, 0xFF, 0xDE, 0x7F, 0xFF, 0xFF, 0xFF, 0xFE, 0x7F, 0xFF, 0xFF, 0xFF, 0xFF, 0xFF,
    0xFF, 0xFF, 0xFF, 0xFF, 0xCF, 0x1F, 0xFF, 0xFF, 0xFF, 0xF8, 0xFF, 0xFF, 0xFF, 0xFF, 0xFF, 0xFF,
    0xFF, 0xFF, 0xFF, 0xFF, 0xFF, 0xC0, 0xFF, 0xFF, 0xFF, 0x03, 0xFF, 0xFF, 0xFF, 0xFF, 0xFF, 0xFF,
    0xFF, 0xFF, 0xFF, 0xFF, 0xFF, 0xFE, 0x00, 0x00, 0x00, 0x7F, 0xFF, 0xFF, 0xFF, 0xFF, 0xFF, 0xFF,
    0xFF, 0xFF, 0xFF, 0xFF, 0xFF, 0xFF, 0xFF, 0xFF, 0xFF, 0xFF, 0xFF, 0xFF, 0xFF, 0xFF, 0xFF, 0xFF,
    0xFF, 0xFF, 0xFF, 0xFF, 0xFF, 0xFF, 0xFF, 0xFF, 0xFF, 0xFF, 0xFF, 0xFF, 0xFF, 0xFF, 0xFF, 0xFF,
    0xFF, 0xFF, 0xFF, 0xFF, 0xFF, 0xFF, 0xFF, 0xFF, 0xFF, 0xFF, 0xFF, 0xFF, 0xFF, 0xFF, 0xFF, 0xFF,
    0xFF, 0xFF, 0xFF, 0xFF, 0xFF, 0xFF, 0xFF, 0xFF, 0xFF, 0xFF, 0xFF, 0xFF, 0xFF, 0xFF, 0xFF, 0xFF,
    0xFF, 0xFF, 0xFF, 0xFF, 0xFF, 0xFF, 0xFF, 0xFF, 0xFF, 0xFF, 0xFF, 0xFF, 0xFF, 0xFF, 0xFF, 0xFF,
    0xFF, 0xFF, 0xFF, 0xFF, 0xFF, 0xFF, 0xFF, 0xFF, 0xFF, 0xFF, 0xFF, 0xFF, 0xFF, 0xFF, 0xFF, 0xFF,
    0xFF, 0xFF, 0xFF, 0xFF, 0xFF, 0xFF, 0xFF, 0xFF, 0xFF, 0xFF, 0xFF, 0xFF, 0xFF, 0xFF, 0xFF, 0xFF,
    0xFF, 0xFF, 0xFF, 0xFF, 0xFF, 0xFF, 0xFF, 0xFF, 0xFF, 0xFF, 0xFF, 0xFF, 0xFF, 0xFF, 0xFF, 0xFF,
    0xFF, 0xFF, 0xFF, 0xFF, 0xFF, 0xFF, 0xFF, 0xFF, 0xFF, 0xFF, 0xFF, 0xFF, 0xFF, 0xFF, 0xFF, 0xFF,
    0xFF, 0xFF, 0xFF, 0xFF, 0xFF, 0xFF, 0xFF, 0xFF, 0xFF, 0xFF, 0xFF, 0xFF, 0xFF, 0xFF, 0xFF, 0xFF,
    0xFF, 0xFF, 0xFF, 0xFF, 0xFF, 0xFF, 0xFF, 0xFF, 0xFF, 0xFF, 0xFF, 0xFF, 0xFF, 0xFF, 0xFF, 0xFF,
    0xFF, 0xFF, 0xFF, 0xFF, 0xFF, 0xFF, 0xFF, 0xFF, 0xFF, 0xFF, 0xFF, 0xFF, 0xFF, 0xFF, 0xFF, 0xFF,
    0xFF, 0xFF, 0xFF, 0xFF, 0xFF, 0xFF, 0xFF, 0xFF, 0xFF, 0xFF, 0xFF, 0xFF, 0xFF, 0xFF, 0xFF, 0xFF
};

const unsigned char image_data_dying_2[] = {
    0xFF, 0xFF, 0xFF, 0xFF, 0xFF, 0xFF, 0xFF, 0xFF, 0xFF, 0xFF, 0xFF, 0xFF, 0xFF, 0xFF, 0xFF, 0xFF,
    0xFF, 0xFF, 0xFF, 0xFF, 0xFF, 0xFF, 0xFF, 0xFF, 0xFF, 0xFF, 0xFF, 0xFF, 0xFF, 0xFF, 0xFF, 0xFF,
    0xFF, 0xFF, 0xFF, 0xFF, 0xFF, 0xFF, 0xFF, 0xFF, 0xFF, 0xFF, 0xFF, 0xFF, 0xFF, 0xFF, 0xFF, 0xFF,
    0xFF, 0xFF, 0xFF, 0xFF, 0xFF, 0xFF, 0xFF, 0xFF, 0xFF, 0xFF, 0xFF, 0xFF, 0xFF, 0xFF, 0xFF, 0xFF,
    0xFF, 0xFF, 0xFF, 0xFF, 0xFF, 0xFF, 0xFF, 0xFF, 0xFF, 0xFF, 0xFF, 0xFF, 0xFF, 0xFF, 0xFF, 0xFF,
    0xFF, 0xFF, 0xFF, 0xFF, 0xFF, 0xFF, 0xFF, 0xFF, 0xFF, 0xFF, 0xFF, 0xFF, 0xFF, 0xFF, 0xFF, 0xFF,
    0xFF, 0xFF, 0xFF, 0xFF, 0xFF, 0xFF, 0xFF, 0xFF, 0xFF, 0xFF, 0xFF, 0xFF, 0xFF, 0xFF, 0xFF, 0xFF,
    0xFF, 0xFF, 0xFF, 0xFF, 0xFF, 0xFF, 0xFF, 0xFF, 0xFF, 0xFF, 0xFF, 0xFF, 0xFF, 0xFF, 0xFF, 0xFF,
    0xFF, 0xFF, 0xFF, 0xFF, 0xFF, 0xFF, 0xFF, 0xFF, 0xFF, 0xFF, 0xFF, 0xFF, 0xFF, 0xFF, 0xFF, 0xFF,
    0xFF, 0xFF, 0xFF, 0xFF, 0xFF, 0xFF, 0xFF, 0xFF, 0xFF, 0xFF, 0xFF, 0xFF, 0xFF, 0xFF, 0xFF, 0xFF,
    0xFF, 0xFF, 0xFF, 0xFF, 0xFF, 0xFF, 0xFF, 0xFF, 0xFF, 0xFF, 0xFF, 0xFF, 0xFF, 0xFF, 0xFF, 0xFF,
    0xFF, 0xFF, 0xFF, 0xFF, 0xFF, 0xFF, 0xFF, 0xFF, 0xFF, 0xFF, 0xFF, 0xFF, 0xFF, 0xFF, 0xFF, 0xFF,
    0xFF, 0xFF, 0xFF, 0xFF, 0xFF, 0xFF, 0xFF, 0xFF, 0xFF, 0xFF, 0xFF, 0xFF, 0xFF, 0xFF, 0xFF, 0xFF,
    0xFF, 0xFF, 0xFF, 0xFF, 0xFF, 0xFF, 0xFF, 0xFF, 0xFF, 0xFF, 0xFF, 0xFF, 0xFF, 0xFF, 0xFF, 0xFF,
    0xFF, 0xFF, 0xFF, 0xFF, 0xFF, 0xFF, 0xFF, 0xFF, 0xFF, 0xFF, 0xFF, 0xFF, 0xFF, 0xFF, 0xFF, 0xFF,
    0xFF, 0xFF, 0xFF, 0xFF, 0xFF, 0xFF, 0xFF, 0xFF, 0xFF, 0xFF, 0xFF, 0xFF, 0xFF, 0xFF, 0xFF, 0xFF,
    0xFF, 0xFF, 0xFF, 0xFF, 0xFF, 0xFF, 0xFF, 0xFF, 0xFF, 0xC0, 0x0F, 0xFF, 0xFF, 0xFF, 0xFF, 0xFF,
    0xFF, 0xFF, 0xFF, 0xFF, 0xFF, 0xFF, 0xFF, 0xFF, 0xFC, 0x3F, 0xE3, 0xFF, 0xFF, 0xFF, 0xFF, 0xFF,
    0xFF, 0xFF, 0xFF, 0xFF, 0xFF, 0x80, 0x1F, 0xFF, 0xF3, 0xFF, 0xF0, 0xFF, 0xFF, 0xFF, 0xFF, 0xFF,
    0xFF, 0xFF, 0xFF, 0xFF, 0xFC, 0x7F, 0xC7, 0xFF, 0xCF, 0xFF, 0xCA, 0x7F, 0xFF, 0xFF, 0xFF, 0xFF,
    0xFF, 0xFF, 0xFF, 0xFF, 0xF1, 0xFF, 0xF0, 0x00, 0x1F, 0xFF, 0x32, 0xFF, 0xFF, 0xFF, 0xFF, 0xFF,
    0xFF, 0xFF, 0xFF, 0xFF, 0xC7, 0xFF, 0xFF, 0xFF, 0xFF, 0xFE, 0x76, 0xFF, 0xFF, 0xFF, 0xFF, 0xFF,
    0xFF, 0xFF, 0xFF, 0xFF, 0x38, 0xFF, 0xFF, 0xFF, 0xFF, 0xFE, 0xE6, 0xFF, 0xFF, 0xFF, 0xFF, 0xFF,
    0xFF, 0xFF, 0xFF, 0xFC, 0x42, 0xFF, 0xFF, 0xFF, 0xFF, 0xFD, 0xF2, 0xFF, 0xFF, 0xFF, 0xFF, 0xFF,
    0xFF, 0xFF, 0xFF, 0xFD, 0xCB, 0xFF, 0xFF, 0xFF, 0xFF, 0xFF, 0xE2, 0xFF, 0xFF, 0xFF, 0xFF, 0xFF,
    0xFF, 0xFF, 0xFF, 0xF9, 0xE7, 0xFF, 0xFF, 0xFF, 0xFF, 0xFF, 0xC6, 0xFF, 0xFF, 0xFF, 0xFF, 0xFF,
    0xFF, 0xFF, 0xFF, 0xF8, 0x77, 0xFF, 0xFF, 0xFF, 0xFF, 0xFF, 0xF4, 0xFF, 0xFF, 0xFF, 0xFF, 0xFF,
    0xFF, 0xFF, 0xFF, 0xFF, 0x1F, 0xFF, 0xFF, 0xFF, 0xFF, 0xFF, 0xE5, 0xFF, 0xFF, 0xFF, 0xFF, 0xFF,
    0xFF, 0xFF, 0xFF, 0xFF, 0xDF, 0xFF, 0xFF, 0xFF, 0xFF, 0xFF, 0xF9, 0xCF, 0xFF, 0xFF, 0xFF, 0xFF,
    0xFF, 0xFF, 0xFF, 0xFF, 0xDF, 0xFF, 0xFF, 0xFF, 0xFF, 0xFF, 0xFF, 0x9F, 0xFF, 0xFF, 0xFF, 0xFF,
    0xFF, 0xFF, 0xFF, 0xFF, 0xDF, 0xFF, 0xF7, 0xFF, 0xFF, 0xFF, 0xFF, 0x3F, 0xFF, 0xFF, 0xFF, 0xFF,
    0xFF, 0xFF, 0xFF, 0xC0, 0x1F, 0xFF, 0xF1, 0xFF, 0x8F, 0xFF, 0xF8, 0xFF, 0xFF, 0xFF, 0xFF, 0xFF,
    0xFF, 0xFF, 0xFF, 0x3F, 0xFF, 0xFF, 0xE7, 0xFF, 0xE7, 0xFF, 0xF8, 0xFF, 0xFF, 0xFF, 0xFF, 0xFF,
    0xFF, 0xFF, 0xFF, 0xFE, 0x3F, 0xFF, 0x8F, 0xFF, 0xF1, 0xFF, 0xFE, 0x7F, 0xFF, 0xFF, 0xFF, 0xFF,
    0xFF, 0xFF, 0xFF, 0xFC, 0xFF, 0xFE, 0x1F, 0xFF, 0xFC, 0x7F, 0xFF, 0x3F, 0xFF, 0xFF, 0xFF, 0xFF,
    0xFF, 0xFF, 0xFF, 0xFD, 0xFF, 0xFC, 0x7F, 0xFF, 0xFE, 0x3F, 0xC3, 0xBF, 0xFF, 0xFF, 0xFF, 0xFF,
    0xFF, 0xFF, 0xFF, 0xF9, 0xFF, 0xFD, 0xFF, 0xFF, 0xFF, 0xBF, 0xF8, 0x9F, 0xFF, 0xFF, 0xFF, 0xFF,
    0xFF, 0xFF, 0xFF, 0xFB, 0xDF, 0xFF, 0xFF, 0xC7, 0xFF, 0xFF, 0xFE, 0x5F, 0xFF, 0xFF, 0xFF, 0xFF,
    0xFF, 0xFF, 0xFF, 0xFB, 0x9F, 0xFF, 0xFF, 0xE7, 0xFF, 0xDF, 0xFF, 0x7F, 0xFF, 0xFF, 0xFF, 0xFF,
    0xFF, 0xFF, 0xFF, 0xFB, 0x3F, 0xFF, 0xFF, 0xE7, 0xFF, 0xFF, 0xFF, 0x3F, 0xFF, 0xFF, 0xFF, 0xFF,
    0xFF, 0xFF, 0xFF, 0xFF, 0x7F, 0xFF, 0xFF, 0xFF, 0xFF, 0xFF, 0xE0, 0xBF, 0xFF, 0xFF, 0xFF, 0xFF,
    0xFF, 0xFF, 0xFF, 0xFC, 0xDF, 0xFF, 0xFF, 0xC3, 0xFF, 0xFF, 0xFF, 0x3F, 0xFF, 0xFF, 0xFF, 0xFF,
    0xFF, 0xFF, 0xFF, 0xF9, 0xDF, 0xFF, 0xFC, 0x18, 0x3F, 0xFF, 0xFF, 0xBF, 0xFF, 0xFF, 0xFF, 0xFF,
    0xFF, 0xFF, 0xFF, 0xFB, 0xDF, 0xFF, 0xFC, 0xFF, 0xBF, 0xFF, 0xE3, 0xFF, 0xFF, 0xFF, 0xFF, 0xFF,
    0xFF, 0xFF, 0xFF, 0xFF, 0xD3, 0xFF, 0xFE, 0x03, 0x3F, 0xFF, 0xC9, 0xFF, 0xFF, 0xFF, 0xFF, 0xFF,
    0xFF, 0xFF, 0xFF, 0xFF, 0xD9, 0xFF, 0xFF, 0xF9, 0x7F, 0xFF, 0x9D, 0xFF, 0xFF, 0xFF, 0xFF, 0xFF,
    0xFF, 0xFF, 0xFF, 0xFF, 0xDC, 0xFF, 0xFF, 0xFD, 0x7F, 0xFE, 0x7D, 0xFF, 0xFF, 0xFF, 0xFF, 0xFF,
    0xFF, 0xFF, 0xFF, 0xFF, 0xEE, 0x3F, 0xFF, 0xFC, 0x7F, 0xFC, 0xFF, 0xFF, 0xFF, 0xFF, 0xFF, 0xFF,
    0xFF, 0xFF, 0xFF, 0xFF, 0xE7, 0xC3, 0xFF, 0xFE, 0x3F, 0xF3, 0xFF, 0xFF, 0xFF, 0xFF, 0xFF, 0xFF,
    0xFF, 0xFF, 0xFF, 0xFF, 0xF7, 0xF8, 0x1F, 0xFE, 0xBF, 0x87, 0xFF, 0xFF, 0xFF, 0xFF, 0xFF, 0xFF,
    0xFF, 0xFF, 0xFF, 0xFF, 0xFF, 0xFF, 0xE0, 0x00, 0x80, 0x3F, 0xFF, 0xFF, 0xFF, 0xFF, 0xFF, 0xFF,
    0xFF, 0xFF, 0xFF, 0xFF, 0xFF, 0xFF, 0xFF, 0xFE, 0x3F, 0xFF, 0xFF, 0xFF, 0xFF, 0xFF, 0xFF, 0xFF,
    0xFF, 0xFF, 0xFF, 0xFF, 0xFF, 0xFF, 0xFF, 0xFF, 0xFF, 0xFF, 0xFF, 0xFF, 0xFF, 0xFF, 0xFF, 0xFF,
    0xFF, 0xFF, 0xFF, 0xFF, 0xFF, 0xFF, 0xFF, 0xFF, 0xFF, 0xFF, 0xFF, 0xFF, 0xFF, 0xFF, 0xFF, 0xFF,
    0xFF, 0xFF, 0xFF, 0xFF, 0xFF, 0xFF, 0xFF, 0xFF, 0x8F, 0xFF, 0xFF, 0xFF, 0xFF, 0xFF, 0xFF, 0xFF,
    0xFF, 0xFF, 0xFF, 0xFF, 0xFF, 0xFF, 0xFF, 0xFF, 0xAF, 0xFF, 0xFF, 0xFF, 0xFF, 0xFF, 0xFF, 0xFF,
    0xFF, 0xFF, 0xFF, 0xFF, 0xFF, 0xFF, 0xFF, 0xFF, 0x8F, 0xFF, 0xFF, 0xFF, 0xFF, 0xFF, 0xFF, 0xFF,
    0xFF, 0xFF, 0xFF, 0xFF, 0xFF, 0xFF, 0xFF, 0xFF, 0xFF, 0xFF, 0xFF, 0xFF, 0xFF, 0xFF, 0xFF, 0xFF,
    0xFF, 0xFF, 0xFF, 0xFF, 0xFF, 0xFF, 0xFF, 0xFF, 0xFF, 0xFF, 0xFF, 0xFF, 0xFF, 0xFF, 0xFF, 0xFF,
    0xFF, 0xFF, 0xFF, 0xFF, 0xFF, 0xFF, 0xFF, 0xFF, 0xFF, 0xFF, 0xFF, 0xFF, 0xFF, 0xFF, 0xFF, 0xFF,
    0xFF, 0xFF, 0xFF, 0xFF, 0xFF, 0xFF, 0xFF, 0xFF, 0xFF, 0xFF, 0xFF, 0xFF, 0xFF, 0xFF, 0xFF, 0xFF,
    0xFF, 0xFF, 0xFF, 0xFF, 0xFF, 0xFF, 0xFF, 0xFF, 0xFF, 0xFF, 0xFF, 0xFF, 0xFF, 0xFF, 0xFF, 0xFF,
    0xFF, 0xFF, 0xFF, 0xFF, 0xFF, 0xFF, 0xFF, 0xFF, 0xFF, 0xFF, 0xFF, 0xFF, 0xFF, 0xFF, 0xFF, 0xFF,
    0xFF, 0xFF, 0xFF, 0xFF, 0xFF, 0xFF, 0xFF, 0xFF, 0xFF, 0xFF, 0xFF, 0xFF, 0xFF, 0xFF, 0xFF, 0xFF
};

// DEBOUNCING CODE
uint32_t adc0 = 0;

#define ADC_SAMPLES 10  // Number of samples for averaging
uint16_t adc_buffer[ADC_SAMPLES] = {0};  // Store previous readings
uint8_t adc_index = 0;  // Index for the circular buffer

double debounce_adc_reading(uint16_t new_reading) {
 // Store new reading
 adc_buffer[adc_index] = new_reading;
 adc_index = (adc_index + 1) % ADC_SAMPLES;

// Calculate the average
 uint32_t sum = 0;
 for (uint8_t i = 0; i < ADC_SAMPLES; i++) {
	sum += adc_buffer[i];
 }
 return ((double)sum / ADC_SAMPLES);
}

// Global timer for changing default image
uint32_t last_active_time = 0;  // Timestamp of the last valid reading
uint8_t inactivity_stage = 0;   // Tracks which default image to show

// Animation
uint8_t frame_toggle = 0;  // Toggles between frames for animation
uint32_t last_frame_time = 0;  // Last time a frame switch happened
#define FRAME_INTERVAL 500  // Time between frames in ms (500 ms = 0.5s)

/* USER CODE END 0 */

int main(void)
{

  /* MCU Configuration--------------------------------------------------------*/

  /* Reset of all peripherals, Initializes the Flash interface and the Systick. */
  HAL_Init();

  /* Configure the system clock */
  SystemClock_Config();

  /* Initialize all configured peripherals */
  MX_GPIO_Init();
  MX_DMA_Init();
  MX_SPI2_Init();
  MX_TSC_Init();
  MX_USB_PCD_Init();
  MX_I2C1_Init();
  MX_ADC_Init();
  /* USER CODE BEGIN 2 */
  ssd1306_Init();
//  HAL_ADCEx_Calibration_Start(&hadc);
  HAL_ADC_Start_DMA(&hadc,(uint32_t*)&adc0,1);
  /* USER CODE END 2 */

  /* Infinite loop */
  /* USER CODE BEGIN WHILE */
  double adc0_v = 0;
  char adc0_str[64];

  while (1) {
	  // Smooth ADC reading using the moving average
	  double smoothed_adc = debounce_adc_reading(adc0);

	  // Convert to voltage
	  adc0_v = (smoothed_adc * 3.3) / 4096.0;

	  // Display ADC value
	  snprintf(adc0_str, sizeof(adc0_str), "%.3f", adc0_v);
	  ssd1306_Fill(Black);
	  ssd1306_SetCursor(0, 48);
	  ssd1306_WriteString(adc0_str, Font_6x8, White);

	  ssd1306_SetCursor(0, 0);
	  uint32_t current_time = HAL_GetTick(); // Get current time in ms

	  // Frame toggle for animation
	  if ((current_time - last_frame_time) >= FRAME_INTERVAL) {
		  frame_toggle = !frame_toggle;  // Switch frames
		  last_frame_time = current_time;
	  }

	  if (adc0_v > 0.1) {
		  // Reset inactivity timer and stage
		  last_active_time = current_time;
		  inactivity_stage = 0;

		  if (frame_toggle) {
			  ssd1306_DrawBitmap(0, 0, image_data_happy_1, 128, 64, White);
		  } else {
			  ssd1306_DrawBitmap(0, 0, image_data_happy_2, 128, 64, White);
		  }

		  ssd1306_UpdateScreen();
		  HAL_Delay(500);
	  }
	  else {
		  // Check inactivity duration
		  uint32_t inactive_duration = current_time - last_active_time;

		  // Update inactivity stage based on time
		  if (inactive_duration > 1800000) {  // 30 minutes
			  inactivity_stage = 3;
		  }
		  else if (inactive_duration > 10000) {  // 10 seconds
			  inactivity_stage = 2;
		  }
		  else if (inactive_duration > 5000) {  // 5 seconds
			  inactivity_stage = 1;
		  }

		  // Display animated images based on inactivity stage
		  switch (inactivity_stage) {
			  case 0:
				  if (frame_toggle) {
					  ssd1306_DrawBitmap(0, 0, image_data_cry_1, 128, 64, White);
				  } else {
					  ssd1306_DrawBitmap(0, 0, image_data_cry_2, 128, 64, White);
				  }
				  break;
			  case 1:
				  if (frame_toggle) {
					  ssd1306_DrawBitmap(0, 0, image_data_dying_1, 128, 64, White);
				  } else {
					  ssd1306_DrawBitmap(0, 0, image_data_dying_2, 128, 64, White);
				  }
				  break;
			  case 2:
				  ssd1306_SetCursor(0, 0);
				  ssd1306_WriteString("Dead", Font_6x8, White);
				  break;
			  case 3:
				  ssd1306_SetCursor(0, 0);
				  ssd1306_WriteString("Super dead!", Font_6x8, White);
				  break;
		  }

		  ssd1306_UpdateScreen();
		  HAL_Delay(100);
	  }

    /* USER CODE END WHILE */

  }
}

void SystemClock_Config(void)
{
  RCC_OscInitTypeDef RCC_OscInitStruct = {0};
  RCC_ClkInitTypeDef RCC_ClkInitStruct = {0};
  RCC_PeriphCLKInitTypeDef PeriphClkInit = {0};

  /** Initializes the RCC Oscillators according to the specified parameters
  * in the RCC_OscInitTypeDef structure.
  */
  RCC_OscInitStruct.OscillatorType = RCC_OSCILLATORTYPE_HSI|RCC_OSCILLATORTYPE_HSI14
                              |RCC_OSCILLATORTYPE_HSI48;
  RCC_OscInitStruct.HSIState = RCC_HSI_ON;
  RCC_OscInitStruct.HSI48State = RCC_HSI48_ON;
  RCC_OscInitStruct.HSI14State = RCC_HSI14_ON;
  RCC_OscInitStruct.HSICalibrationValue = RCC_HSICALIBRATION_DEFAULT;
  RCC_OscInitStruct.HSI14CalibrationValue = 16;
  RCC_OscInitStruct.PLL.PLLState = RCC_PLL_ON;
  RCC_OscInitStruct.PLL.PLLSource = RCC_PLLSOURCE_HSI;
  RCC_OscInitStruct.PLL.PLLMUL = RCC_PLL_MUL6;
  RCC_OscInitStruct.PLL.PREDIV = RCC_PREDIV_DIV1;
  if (HAL_RCC_OscConfig(&RCC_OscInitStruct) != HAL_OK)
  {
    Error_Handler();
  }

  /** Initializes the CPU, AHB and APB buses clocks
  */
  RCC_ClkInitStruct.ClockType = RCC_CLOCKTYPE_HCLK|RCC_CLOCKTYPE_SYSCLK
                              |RCC_CLOCKTYPE_PCLK1;
  RCC_ClkInitStruct.SYSCLKSource = RCC_SYSCLKSOURCE_PLLCLK;
  RCC_ClkInitStruct.AHBCLKDivider = RCC_SYSCLK_DIV1;
  RCC_ClkInitStruct.APB1CLKDivider = RCC_HCLK_DIV1;

  if (HAL_RCC_ClockConfig(&RCC_ClkInitStruct, FLASH_LATENCY_1) != HAL_OK)
  {
    Error_Handler();
  }
  PeriphClkInit.PeriphClockSelection = RCC_PERIPHCLK_USB|RCC_PERIPHCLK_I2C1;
  PeriphClkInit.I2c1ClockSelection = RCC_I2C1CLKSOURCE_HSI;
  PeriphClkInit.UsbClockSelection = RCC_USBCLKSOURCE_HSI48;

  if (HAL_RCCEx_PeriphCLKConfig(&PeriphClkInit) != HAL_OK)
  {
    Error_Handler();
  }
}

static void MX_ADC_Init(void)
{

  ADC_ChannelConfTypeDef sConfig = {0};

  /** Configure the global features of the ADC (Clock, Resolution, Data Alignment and number of conversion)
  */
  hadc.Instance = ADC1;
  hadc.Init.ClockPrescaler = ADC_CLOCK_ASYNC_DIV1;
  hadc.Init.Resolution = ADC_RESOLUTION_12B;
  hadc.Init.DataAlign = ADC_DATAALIGN_RIGHT;
  hadc.Init.ScanConvMode = ADC_SCAN_DIRECTION_FORWARD;
  hadc.Init.EOCSelection = ADC_EOC_SINGLE_CONV;
  hadc.Init.LowPowerAutoWait = DISABLE;
  hadc.Init.LowPowerAutoPowerOff = DISABLE;
  hadc.Init.ContinuousConvMode = ENABLE;
  hadc.Init.DiscontinuousConvMode = DISABLE;
  hadc.Init.ExternalTrigConv = ADC_SOFTWARE_START;
  hadc.Init.ExternalTrigConvEdge = ADC_EXTERNALTRIGCONVEDGE_NONE;
  hadc.Init.DMAContinuousRequests = ENABLE;
  hadc.Init.Overrun = ADC_OVR_DATA_PRESERVED;
  if (HAL_ADC_Init(&hadc) != HAL_OK)
  {
    Error_Handler();
  }

  /** Configure for the selected ADC regular channel to be converted.
  */
  sConfig.Channel = ADC_CHANNEL_1;
  sConfig.Rank = ADC_RANK_CHANNEL_NUMBER;
  sConfig.SamplingTime = ADC_SAMPLETIME_239CYCLES_5;
  if (HAL_ADC_ConfigChannel(&hadc, &sConfig) != HAL_OK)
  {
    Error_Handler();
  }

}

static void MX_I2C1_Init(void)
{

  hi2c1.Instance = I2C1;
  hi2c1.Init.Timing = 0x0010020A;
  hi2c1.Init.OwnAddress1 = 0;
  hi2c1.Init.AddressingMode = I2C_ADDRESSINGMODE_7BIT;
  hi2c1.Init.DualAddressMode = I2C_DUALADDRESS_DISABLE;
  hi2c1.Init.OwnAddress2 = 0;
  hi2c1.Init.OwnAddress2Masks = I2C_OA2_NOMASK;
  hi2c1.Init.GeneralCallMode = I2C_GENERALCALL_DISABLE;
  hi2c1.Init.NoStretchMode = I2C_NOSTRETCH_DISABLE;
  if (HAL_I2C_Init(&hi2c1) != HAL_OK)
  {
    Error_Handler();
  }

  /** Configure Analogue filter
  */
  if (HAL_I2CEx_ConfigAnalogFilter(&hi2c1, I2C_ANALOGFILTER_ENABLE) != HAL_OK)
  {
    Error_Handler();
  }

  /** Configure Digital filter
  */
  if (HAL_I2CEx_ConfigDigitalFilter(&hi2c1, 0) != HAL_OK)
  {
    Error_Handler();
  }

}

static void MX_SPI2_Init(void)
{

  /* SPI2 parameter configuration*/
  hspi2.Instance = SPI2;
  hspi2.Init.Mode = SPI_MODE_MASTER;
  hspi2.Init.Direction = SPI_DIRECTION_2LINES;
  hspi2.Init.DataSize = SPI_DATASIZE_4BIT;
  hspi2.Init.CLKPolarity = SPI_POLARITY_LOW;
  hspi2.Init.CLKPhase = SPI_PHASE_1EDGE;
  hspi2.Init.NSS = SPI_NSS_SOFT;
  hspi2.Init.BaudRatePrescaler = SPI_BAUDRATEPRESCALER_4;
  hspi2.Init.FirstBit = SPI_FIRSTBIT_MSB;
  hspi2.Init.TIMode = SPI_TIMODE_DISABLE;
  hspi2.Init.CRCCalculation = SPI_CRCCALCULATION_DISABLE;
  hspi2.Init.CRCPolynomial = 7;
  hspi2.Init.CRCLength = SPI_CRC_LENGTH_DATASIZE;
  hspi2.Init.NSSPMode = SPI_NSS_PULSE_ENABLE;
  if (HAL_SPI_Init(&hspi2) != HAL_OK)
  {
    Error_Handler();
  }

}

static void MX_TSC_Init(void)
{

  /** Configure the TSC peripheral
  */
  htsc.Instance = TSC;
  htsc.Init.CTPulseHighLength = TSC_CTPH_2CYCLES;
  htsc.Init.CTPulseLowLength = TSC_CTPL_2CYCLES;
  htsc.Init.SpreadSpectrum = DISABLE;
  htsc.Init.SpreadSpectrumDeviation = 1;
  htsc.Init.SpreadSpectrumPrescaler = TSC_SS_PRESC_DIV1;
  htsc.Init.PulseGeneratorPrescaler = TSC_PG_PRESC_DIV4;
  htsc.Init.MaxCountValue = TSC_MCV_8191;
  htsc.Init.IODefaultMode = TSC_IODEF_OUT_PP_LOW;
  htsc.Init.SynchroPinPolarity = TSC_SYNC_POLARITY_FALLING;
  htsc.Init.AcquisitionMode = TSC_ACQ_MODE_NORMAL;
  htsc.Init.MaxCountInterrupt = DISABLE;
  htsc.Init.ChannelIOs = TSC_GROUP1_IO3|TSC_GROUP2_IO3|TSC_GROUP3_IO2;
  htsc.Init.ShieldIOs = 0;
  htsc.Init.SamplingIOs = TSC_GROUP1_IO4|TSC_GROUP2_IO4|TSC_GROUP3_IO3;
  if (HAL_TSC_Init(&htsc) != HAL_OK)
  {
    Error_Handler();
  }

}

static void MX_USB_PCD_Init(void)
{

  hpcd_USB_FS.Instance = USB;
  hpcd_USB_FS.Init.dev_endpoints = 8;
  hpcd_USB_FS.Init.speed = PCD_SPEED_FULL;
  hpcd_USB_FS.Init.phy_itface = PCD_PHY_EMBEDDED;
  hpcd_USB_FS.Init.low_power_enable = DISABLE;
  hpcd_USB_FS.Init.lpm_enable = DISABLE;
  hpcd_USB_FS.Init.battery_charging_enable = DISABLE;
  if (HAL_PCD_Init(&hpcd_USB_FS) != HAL_OK)
  {
    Error_Handler();
  }

}

static void MX_DMA_Init(void)
{

  /* DMA controller clock enable */
  __HAL_RCC_DMA1_CLK_ENABLE();

  /* DMA interrupt init */
  /* DMA1_Channel1_IRQn interrupt configuration */
  HAL_NVIC_SetPriority(DMA1_Channel1_IRQn, 0, 0);
  HAL_NVIC_EnableIRQ(DMA1_Channel1_IRQn);

}

static void MX_GPIO_Init(void)
{
  GPIO_InitTypeDef GPIO_InitStruct = {0};

  /* GPIO Ports Clock Enable */
  __HAL_RCC_GPIOC_CLK_ENABLE();
  __HAL_RCC_GPIOA_CLK_ENABLE();
  __HAL_RCC_GPIOB_CLK_ENABLE();

  /*Configure GPIO pin Output Level */
  HAL_GPIO_WritePin(GPIOC, NCS_MEMS_SPI_Pin|EXT_RESET_Pin|LD3_Pin|LD6_Pin
                          |LD4_Pin|LD5_Pin, GPIO_PIN_RESET);

  /*Configure GPIO pins : NCS_MEMS_SPI_Pin EXT_RESET_Pin LD3_Pin LD6_Pin
                           LD4_Pin LD5_Pin */
  GPIO_InitStruct.Pin = NCS_MEMS_SPI_Pin|EXT_RESET_Pin|LD3_Pin|LD6_Pin
                          |LD4_Pin|LD5_Pin;
  GPIO_InitStruct.Mode = GPIO_MODE_OUTPUT_PP;
  GPIO_InitStruct.Pull = GPIO_NOPULL;
  GPIO_InitStruct.Speed = GPIO_SPEED_FREQ_LOW;
  HAL_GPIO_Init(GPIOC, &GPIO_InitStruct);

  /*Configure GPIO pins : MEMS_INT1_Pin MEMS_INT2_Pin */
  GPIO_InitStruct.Pin = MEMS_INT1_Pin|MEMS_INT2_Pin;
  GPIO_InitStruct.Mode = GPIO_MODE_EVT_RISING;
  GPIO_InitStruct.Pull = GPIO_NOPULL;
  HAL_GPIO_Init(GPIOC, &GPIO_InitStruct);

  /*Configure GPIO pin : B1_Pin */
  GPIO_InitStruct.Pin = B1_Pin;
  GPIO_InitStruct.Mode = GPIO_MODE_EVT_RISING;
  GPIO_InitStruct.Pull = GPIO_NOPULL;
  HAL_GPIO_Init(B1_GPIO_Port, &GPIO_InitStruct);

  /*Configure GPIO pins : I2C2_SCL_Pin I2C2_SDA_Pin */
  GPIO_InitStruct.Pin = I2C2_SCL_Pin|I2C2_SDA_Pin;
  GPIO_InitStruct.Mode = GPIO_MODE_AF_OD;
  GPIO_InitStruct.Pull = GPIO_PULLUP;
  GPIO_InitStruct.Speed = GPIO_SPEED_FREQ_HIGH;
  GPIO_InitStruct.Alternate = GPIO_AF1_I2C2;
  HAL_GPIO_Init(GPIOB, &GPIO_InitStruct);

}

void Error_Handler(void)
{
  __disable_irq();
  while (1)
  {
  }
}
